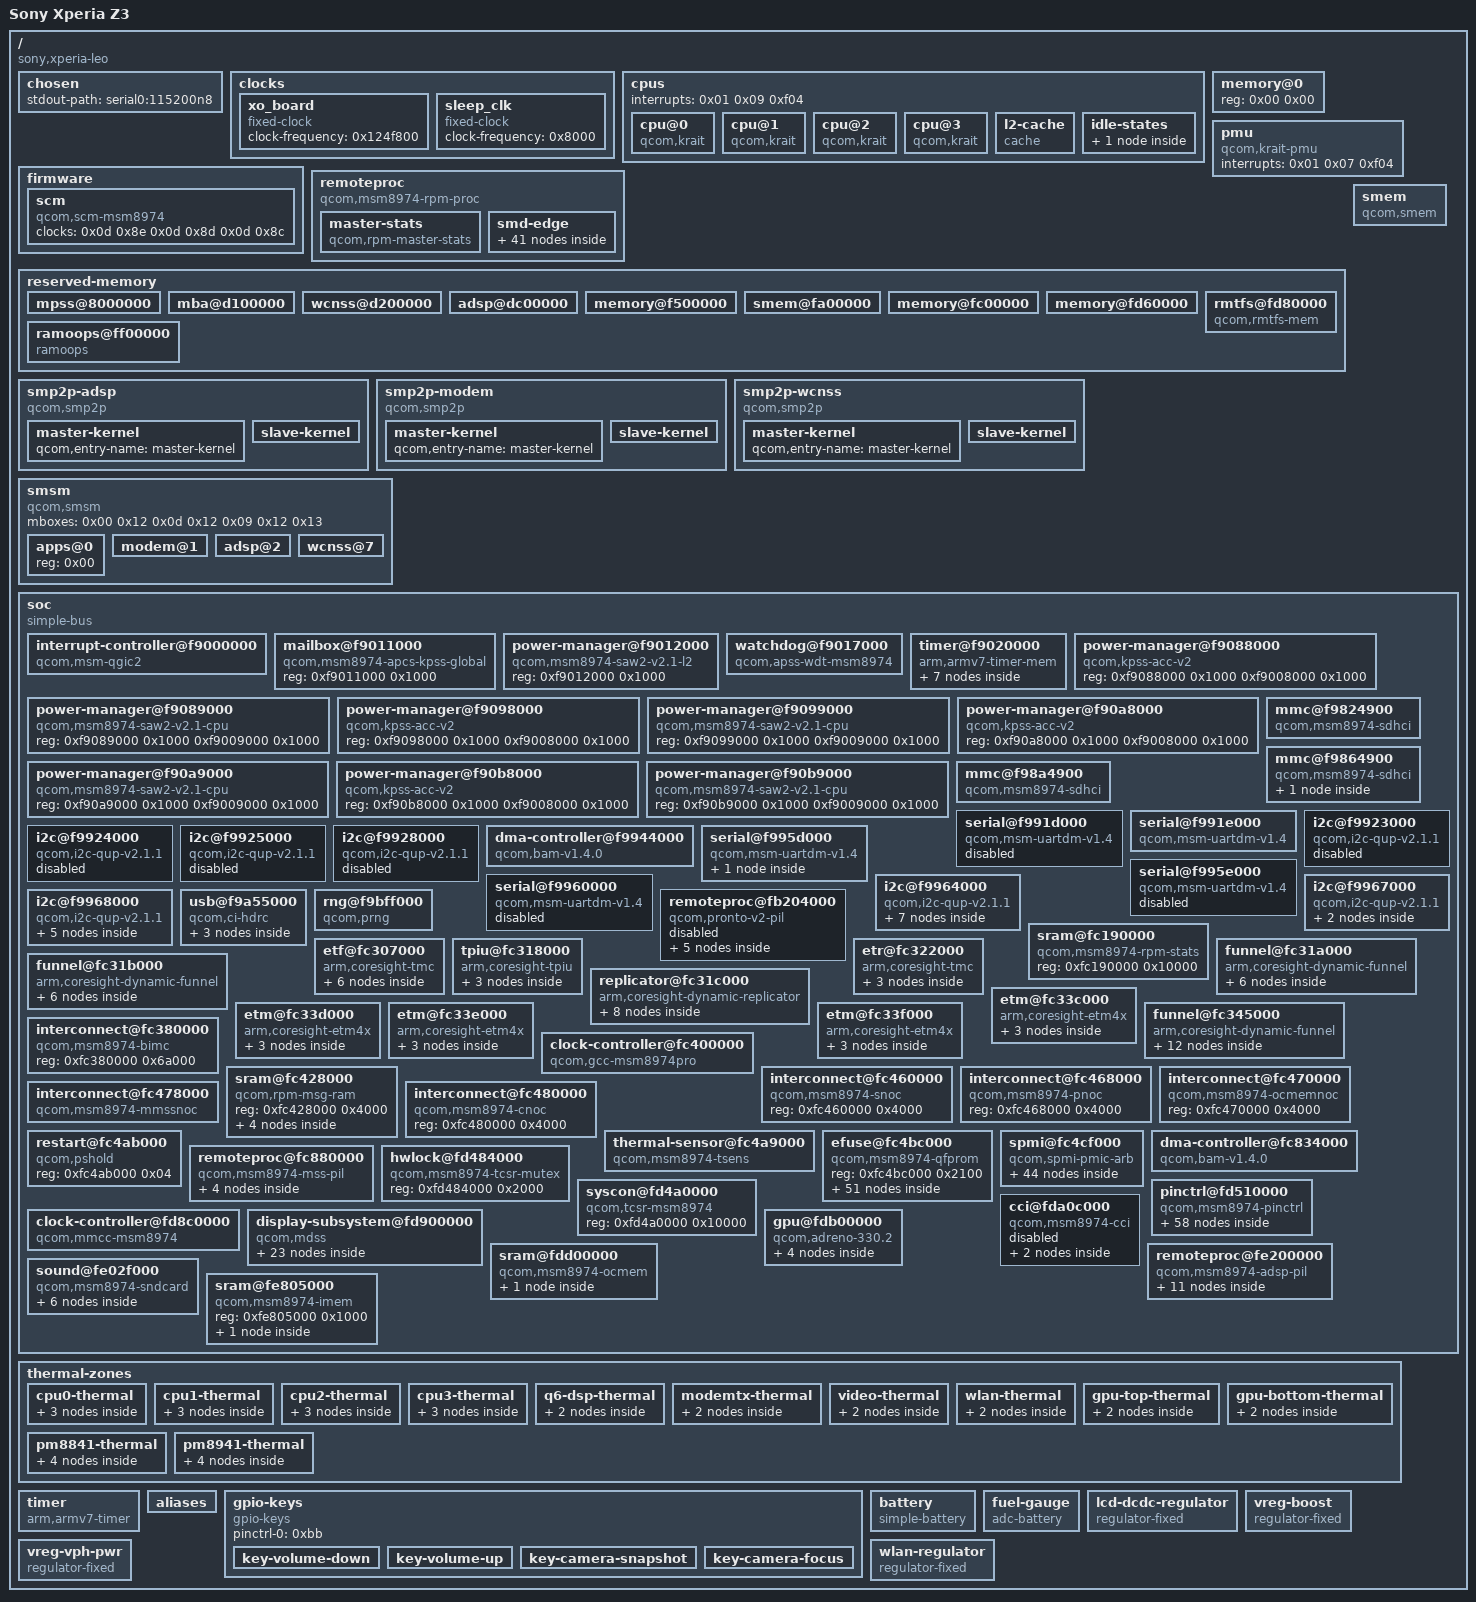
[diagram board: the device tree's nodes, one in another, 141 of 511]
/dts-v1/;

/ {
	#address-cells = <0x01>;
	#size-cells = <0x01>;
	interrupt-parent = <0x01>;
	model = "Sony Xperia Z3";
	compatible = "sony,xperia-leo", "qcom,msm8974pro", "qcom,msm8974";
	chassis-type = "handset";

	chosen {
		stdout-path = "serial0:115200n8";
	};

	clocks {

		xo_board {
			compatible = "fixed-clock";
			#clock-cells = <0x00>;
			clock-frequency = <0x124f800>;
			phandle = <0x13>;
		};

		sleep_clk {
			compatible = "fixed-clock";
			#clock-cells = <0x00>;
			clock-frequency = <0x8000>;
			phandle = <0x1c>;
		};
	};

	cpus {
		#address-cells = <0x01>;
		#size-cells = <0x00>;
		interrupts = <0x01 0x09 0xf04>;

		cpu@0 {
			compatible = "qcom,krait";
			enable-method = "qcom,kpss-acc-v2";
			device_type = "cpu";
			reg = <0x00>;
			next-level-cache = <0x02>;
			qcom,acc = <0x03>;
			qcom,saw = <0x04>;
			cpu-idle-states = <0x05>;
			phandle = <0x57>;
		};

		cpu@1 {
			compatible = "qcom,krait";
			enable-method = "qcom,kpss-acc-v2";
			device_type = "cpu";
			reg = <0x01>;
			next-level-cache = <0x02>;
			qcom,acc = <0x06>;
			qcom,saw = <0x07>;
			cpu-idle-states = <0x05>;
			phandle = <0x59>;
		};

		cpu@2 {
			compatible = "qcom,krait";
			enable-method = "qcom,kpss-acc-v2";
			device_type = "cpu";
			reg = <0x02>;
			next-level-cache = <0x02>;
			qcom,acc = <0x08>;
			qcom,saw = <0x09>;
			cpu-idle-states = <0x05>;
			phandle = <0x5b>;
		};

		cpu@3 {
			compatible = "qcom,krait";
			enable-method = "qcom,kpss-acc-v2";
			device_type = "cpu";
			reg = <0x03>;
			next-level-cache = <0x02>;
			qcom,acc = <0x0a>;
			qcom,saw = <0x0b>;
			cpu-idle-states = <0x05>;
			phandle = <0x5d>;
		};

		l2-cache {
			compatible = "cache";
			cache-level = <0x02>;
			cache-unified;
			qcom,saw = <0x0c>;
			phandle = <0x02>;
		};

		idle-states {

			cpu-spc {
				compatible = "qcom,idle-state-spc", "arm,idle-state";
				entry-latency-us = <0x96>;
				exit-latency-us = <0xc8>;
				min-residency-us = <0x7d0>;
				phandle = <0x05>;
			};
		};
	};

	firmware {

		scm {
			compatible = "qcom,scm-msm8974", "qcom,scm";
			clocks = <0x0d 0x8e 0x0d 0x8d 0x0d 0x8c>;
			clock-names = "core", "bus", "iface";
		};
	};

	memory@0 {
		device_type = "memory";
		reg = <0x00 0x00>;
	};

	pmu {
		compatible = "qcom,krait-pmu";
		interrupts = <0x01 0x07 0xf04>;
	};

	remoteproc {
		compatible = "qcom,msm8974-rpm-proc", "qcom,rpm-proc";

		master-stats {
			compatible = "qcom,rpm-master-stats";
			qcom,rpm-msg-ram = <0x0e 0x0f 0x10 0x11>;
			qcom,master-names = "APSS", "MPSS", "LPSS", "PRONTO";
		};

		smd-edge {
			interrupts = <0x00 0xa8 0x01>;
			mboxes = <0x12 0x00>;
			qcom,smd-edge = <0x0f>;

			rpm-requests {
				compatible = "qcom,rpm-msm8974", "qcom,smd-rpm";
				qcom,smd-channels = "rpm_requests";

				clock-controller {
					compatible = "qcom,rpmcc-msm8974", "qcom,rpmcc";
					#clock-cells = <0x01>;
					clocks = <0x13>;
					clock-names = "xo";
					phandle = <0x49>;
				};

				power-controller {
					compatible = "qcom,msm8974-rpmpd";
					#power-domain-cells = <0x01>;
					operating-points-v2 = <0x14>;
					phandle = <0x47>;

					opp-table {
						compatible = "operating-points-v2";
						phandle = <0x14>;

						opp1 {
							opp-level = <0x01>;
						};

						opp2 {
							opp-level = <0x02>;
						};

						opp3 {
							opp-level = <0x03>;
						};

						opp4 {
							opp-level = <0x04>;
						};

						opp5 {
							opp-level = <0x05>;
						};

						opp6 {
							opp-level = <0x06>;
						};
					};
				};

				regulators-0 {
					compatible = "qcom,rpm-pm8841-regulators";

					s1 {
						regulator-min-microvolt = <0xa4cb8>;
						regulator-max-microvolt = <0x100590>;
						phandle = <0xa1>;
					};

					s3 {
						regulator-min-microvolt = <0x7a120>;
						regulator-max-microvolt = <0x100590>;
						phandle = <0xa0>;
					};
				};

				regulators-1 {
					compatible = "qcom,rpm-pm8941-regulators";
					vdd_l1_l3-supply = <0x15>;
					vdd_l2_lvs1_2_3-supply = <0x16>;
					vdd_l4_l11-supply = <0x15>;
					vdd_l5_l7-supply = <0x17>;
					vdd_l6_l12_l14_l15-supply = <0x17>;
					vdd_l9_l10_l17_l22-supply = <0x18>;
					vdd_l13_l20_l23_l24-supply = <0x18>;
					vdd_l21-supply = <0x18>;

					s1 {
						regulator-min-microvolt = <0x13d620>;
						regulator-max-microvolt = <0x13d620>;
						regulator-always-on;
						regulator-boot-on;
						phandle = <0x15>;
					};

					s2 {
						regulator-min-microvolt = <0x20ce70>;
						regulator-max-microvolt = <0x20ce70>;
						regulator-boot-on;
						phandle = <0x17>;
					};

					s3 {
						regulator-min-microvolt = <0x1b7740>;
						regulator-max-microvolt = <0x1b7740>;
						regulator-system-load = <0x25990>;
						regulator-always-on;
						regulator-boot-on;
						phandle = <0x16>;
					};

					s4 {
						regulator-min-microvolt = <0x4c4b40>;
						regulator-max-microvolt = <0x4c4b40>;
					};

					l1 {
						regulator-min-microvolt = <0x12b128>;
						regulator-max-microvolt = <0x12b128>;
						regulator-always-on;
						regulator-boot-on;
					};

					l2 {
						regulator-min-microvolt = <0x124f80>;
						regulator-max-microvolt = <0x124f80>;
						phandle = <0xc2>;
					};

					l3 {
						regulator-min-microvolt = <0x124f80>;
						regulator-max-microvolt = <0x124f80>;
					};

					l4 {
						regulator-min-microvolt = <0x12b128>;
						regulator-max-microvolt = <0x12b128>;
					};

					l5 {
						regulator-min-microvolt = <0x1b7740>;
						regulator-max-microvolt = <0x1b7740>;
					};

					l6 {
						regulator-min-microvolt = <0x1b7740>;
						regulator-max-microvolt = <0x1b7740>;
						regulator-boot-on;
						phandle = <0x43>;
					};

					l7 {
						regulator-min-microvolt = <0x1b7740>;
						regulator-max-microvolt = <0x1b7740>;
						regulator-boot-on;
					};

					l8 {
						regulator-min-microvolt = <0x1b7740>;
						regulator-max-microvolt = <0x1b7740>;
					};

					l9 {
						regulator-min-microvolt = <0x1b7740>;
						regulator-max-microvolt = <0x2d0370>;
					};

					l12 {
						regulator-min-microvolt = <0x1b7740>;
						regulator-max-microvolt = <0x1b7740>;
						regulator-always-on;
						regulator-boot-on;
						phandle = <0xa2>;
					};

					l13 {
						regulator-min-microvolt = <0x1b7740>;
						regulator-max-microvolt = <0x2d0370>;
						regulator-boot-on;
						phandle = <0x24>;
					};

					l14 {
						regulator-min-microvolt = <0x1b7740>;
						regulator-max-microvolt = <0x1b7740>;
					};

					l15 {
						regulator-min-microvolt = <0x1f47d0>;
						regulator-max-microvolt = <0x1f47d0>;
					};

					l16 {
						regulator-min-microvolt = <0x2932e0>;
						regulator-max-microvolt = <0x2932e0>;
						regulator-always-on;
					};

					l17 {
						regulator-min-microvolt = <0x2932e0>;
						regulator-max-microvolt = <0x2932e0>;
						regulator-always-on;
						phandle = <0xd0>;
					};

					l18 {
						regulator-min-microvolt = <0x2b7cd0>;
						regulator-max-microvolt = <0x2b7cd0>;
						regulator-always-on;
					};

					l20 {
						regulator-min-microvolt = <0x2d0370>;
						regulator-max-microvolt = <0x2d0370>;
						regulator-system-load = <0x7a120>;
						regulator-allow-set-load;
						regulator-boot-on;
						phandle = <0x1d>;
					};

					l21 {
						regulator-min-microvolt = <0x2d0370>;
						regulator-max-microvolt = <0x2d0370>;
						regulator-system-load = <0x7a120>;
						regulator-allow-set-load;
						regulator-boot-on;
						phandle = <0x23>;
					};

					l22 {
						regulator-min-microvolt = <0x2dc6c0>;
						regulator-max-microvolt = <0x2dc6c0>;
						phandle = <0x36>;
					};

					l23 {
						regulator-min-microvolt = <0x2ab980>;
						regulator-max-microvolt = <0x2ab980>;
					};

					l24 {
						regulator-min-microvolt = <0x2eebb8>;
						regulator-max-microvolt = <0x2eebb8>;
						regulator-boot-on;
						phandle = <0x44>;
					};

					lvs1 {
						regulator-always-on;
						phandle = <0xd1>;
					};

					lvs3 {
						phandle = <0xc3>;
					};
				};
			};
		};
	};

	reserved-memory {
		#address-cells = <0x01>;
		#size-cells = <0x01>;
		ranges;

		mpss@8000000 {
			reg = <0x8000000 0x5100000>;
			no-map;
			phandle = <0xa4>;
		};

		mba@d100000 {
			reg = <0xd100000 0x100000>;
			no-map;
			phandle = <0xa3>;
		};

		wcnss@d200000 {
			reg = <0xd200000 0xa00000>;
			no-map;
			phandle = <0x45>;
		};

		adsp@dc00000 {
			reg = <0xdc00000 0x1900000>;
			no-map;
			phandle = <0xb6>;
		};

		memory@f500000 {
			reg = <0xf500000 0x500000>;
			no-map;
		};

		smem@fa00000 {
			reg = <0xfa00000 0x200000>;
			no-map;
			phandle = <0x19>;
		};

		memory@fc00000 {
			reg = <0xfc00000 0x160000>;
			no-map;
		};

		memory@fd60000 {
			reg = <0xfd60000 0x20000>;
			no-map;
		};

		rmtfs@fd80000 {
			compatible = "qcom,rmtfs-mem";
			reg = <0xfd80000 0x180000>;
			no-map;
			qcom,client-id = <0x01>;
		};
		ramoops@ff00000 {
			compatible = "ramoops";
			reg = <0x0ff00000 0x100000>;
			console-size = <0x80000>;
			record-size = <0x20000>;
		};
	};

	smem {
		compatible = "qcom,smem";
		memory-region = <0x19>;
		qcom,rpm-msg-ram = <0x1a>;
		hwlocks = <0x1b 0x03>;
	};

	smp2p-adsp {
		compatible = "qcom,smp2p";
		qcom,smem = <0x1bb 0x1ad>;
		interrupt-parent = <0x01>;
		interrupts = <0x00 0x9e 0x01>;
		mboxes = <0x12 0x0a>;
		qcom,local-pid = <0x00>;
		qcom,remote-pid = <0x02>;

		master-kernel {
			qcom,entry-name = "master-kernel";
			#qcom,smem-state-cells = <0x01>;
			phandle = <0xb7>;
		};

		slave-kernel {
			qcom,entry-name = "slave-kernel";
			interrupt-controller;
			#interrupt-cells = <0x02>;
			phandle = <0xb5>;
		};
	};

	smp2p-modem {
		compatible = "qcom,smp2p";
		qcom,smem = <0x1b3 0x1ac>;
		interrupt-parent = <0x01>;
		interrupts = <0x00 0x1b 0x01>;
		mboxes = <0x12 0x0e>;
		qcom,local-pid = <0x00>;
		qcom,remote-pid = <0x01>;

		master-kernel {
			qcom,entry-name = "master-kernel";
			#qcom,smem-state-cells = <0x01>;
			phandle = <0x9f>;
		};

		slave-kernel {
			qcom,entry-name = "slave-kernel";
			interrupt-controller;
			#interrupt-cells = <0x02>;
			phandle = <0x9e>;
		};
	};

	smp2p-wcnss {
		compatible = "qcom,smp2p";
		qcom,smem = <0x1c3 0x1af>;
		interrupt-parent = <0x01>;
		interrupts = <0x00 0x8f 0x01>;
		mboxes = <0x12 0x12>;
		qcom,local-pid = <0x00>;
		qcom,remote-pid = <0x04>;

		master-kernel {
			qcom,entry-name = "master-kernel";
			#qcom,smem-state-cells = <0x01>;
			phandle = <0x48>;
		};

		slave-kernel {
			qcom,entry-name = "slave-kernel";
			interrupt-controller;
			#interrupt-cells = <0x02>;
			phandle = <0x46>;
		};
	};

	smsm {
		compatible = "qcom,smsm";
		#address-cells = <0x01>;
		#size-cells = <0x00>;
		mboxes = <0x00 0x12 0x0d 0x12 0x09 0x12 0x13>;

		apps@0 {
			reg = <0x00>;
			#qcom,smem-state-cells = <0x01>;
			phandle = <0x4b>;
		};

		modem@1 {
			reg = <0x01>;
			interrupts = <0x00 0x1a 0x01>;
			interrupt-controller;
			#interrupt-cells = <0x02>;
			phandle = <0xa5>;
		};

		adsp@2 {
			reg = <0x02>;
			interrupts = <0x00 0x9d 0x01>;
			interrupt-controller;
			#interrupt-cells = <0x02>;
		};

		wcnss@7 {
			reg = <0x07>;
			interrupts = <0x00 0x90 0x01>;
			interrupt-controller;
			#interrupt-cells = <0x02>;
		};
	};

	soc {
		#address-cells = <0x01>;
		#size-cells = <0x01>;
		ranges;
		compatible = "simple-bus";

		interrupt-controller@f9000000 {
			compatible = "qcom,msm-qgic2";
			interrupt-controller;
			#interrupt-cells = <0x03>;
			reg = <0xf9000000 0x1000 0xf9002000 0x1000>;
			phandle = <0x01>;
		};

		mailbox@f9011000 {
			compatible = "qcom,msm8974-apcs-kpss-global", "qcom,msm8994-apcs-kpss-global", "syscon";
			reg = <0xf9011000 0x1000>;
			#mbox-cells = <0x01>;
			phandle = <0x12>;
		};

		power-manager@f9012000 {
			compatible = "qcom,msm8974-saw2-v2.1-l2", "qcom,saw2";
			reg = <0xf9012000 0x1000>;
			phandle = <0x0c>;
		};

		watchdog@f9017000 {
			compatible = "qcom,apss-wdt-msm8974", "qcom,kpss-wdt";
			reg = <0xf9017000 0x1000>;
			interrupts = <0x00 0x03 0x01 0x00 0x04 0x01>;
			clocks = <0x1c>;
		};

		timer@f9020000 {
			#address-cells = <0x01>;
			#size-cells = <0x01>;
			ranges;
			compatible = "arm,armv7-timer-mem";
			reg = <0xf9020000 0x1000>;
			clock-frequency = <0x124f800>;

			frame@f9021000 {
				frame-number = <0x00>;
				interrupts = <0x00 0x08 0x04 0x00 0x07 0x04>;
				reg = <0xf9021000 0x1000 0xf9022000 0x1000>;
			};

			frame@f9023000 {
				frame-number = <0x01>;
				interrupts = <0x00 0x09 0x04>;
				reg = <0xf9023000 0x1000>;
				status = "disabled";
			};

			frame@f9024000 {
				frame-number = <0x02>;
				interrupts = <0x00 0x0a 0x04>;
				reg = <0xf9024000 0x1000>;
				status = "disabled";
			};

			frame@f9025000 {
				frame-number = <0x03>;
				interrupts = <0x00 0x0b 0x04>;
				reg = <0xf9025000 0x1000>;
				status = "disabled";
			};

			frame@f9026000 {
				frame-number = <0x04>;
				interrupts = <0x00 0x0c 0x04>;
				reg = <0xf9026000 0x1000>;
				status = "disabled";
			};

			frame@f9027000 {
				frame-number = <0x05>;
				interrupts = <0x00 0x0d 0x04>;
				reg = <0xf9027000 0x1000>;
				status = "disabled";
			};

			frame@f9028000 {
				frame-number = <0x06>;
				interrupts = <0x00 0x0e 0x04>;
				reg = <0xf9028000 0x1000>;
				status = "disabled";
			};
		};

		power-manager@f9088000 {
			compatible = "qcom,kpss-acc-v2";
			reg = <0xf9088000 0x1000 0xf9008000 0x1000>;
			phandle = <0x03>;
		};

		power-manager@f9089000 {
			compatible = "qcom,msm8974-saw2-v2.1-cpu", "qcom,saw2";
			reg = <0xf9089000 0x1000 0xf9009000 0x1000>;
			phandle = <0x04>;
		};

		power-manager@f9098000 {
			compatible = "qcom,kpss-acc-v2";
			reg = <0xf9098000 0x1000 0xf9008000 0x1000>;
			phandle = <0x06>;
		};

		power-manager@f9099000 {
			compatible = "qcom,msm8974-saw2-v2.1-cpu", "qcom,saw2";
			reg = <0xf9099000 0x1000 0xf9009000 0x1000>;
			phandle = <0x07>;
		};

		power-manager@f90a8000 {
			compatible = "qcom,kpss-acc-v2";
			reg = <0xf90a8000 0x1000 0xf9008000 0x1000>;
			phandle = <0x08>;
		};

		power-manager@f90a9000 {
			compatible = "qcom,msm8974-saw2-v2.1-cpu", "qcom,saw2";
			reg = <0xf90a9000 0x1000 0xf9009000 0x1000>;
			phandle = <0x09>;
		};

		power-manager@f90b8000 {
			compatible = "qcom,kpss-acc-v2";
			reg = <0xf90b8000 0x1000 0xf9008000 0x1000>;
			phandle = <0x0a>;
		};

		power-manager@f90b9000 {
			compatible = "qcom,msm8974-saw2-v2.1-cpu", "qcom,saw2";
			reg = <0xf90b9000 0x1000 0xf9009000 0x1000>;
			phandle = <0x0b>;
		};

		mmc@f9824900 {
			compatible = "qcom,msm8974-sdhci", "qcom,sdhci-msm-v4";
			reg = <0xf9824900 0x11c 0xf9824000 0x800>;
			reg-names = "hc", "core";
			interrupts = <0x00 0x7b 0x04 0x00 0x8a 0x04>;
			interrupt-names = "hc_irq", "pwr_irq";
			clocks = <0x0d 0xd7 0x0d 0xd8 0x13 0x0d 0x131 0x0d 0x130>;
			clock-names = "iface", "core", "xo", "cal", "sleep";
			bus-width = <0x08>;
			non-removable;
			status = "okay";
			vmmc-supply = <0x1d>;
			vqmmc-supply = <0x16>;
			pinctrl-0 = <0x1e>;
			pinctrl-1 = <0x1f>;
			pinctrl-names = "default", "sleep";
		};

		mmc@f9864900 {
			compatible = "qcom,msm8974-sdhci", "qcom,sdhci-msm-v4";
			reg = <0xf9864900 0x11c 0xf9864000 0x800>;
			reg-names = "hc", "core";
			interrupts = <0x00 0x7f 0x04 0x00 0xe0 0x04>;
			interrupt-names = "hc_irq", "pwr_irq";
			clocks = <0x0d 0xdd 0x0d 0xde 0x13>;
			clock-names = "iface", "core", "xo";
			bus-width = <0x04>;
			#address-cells = <0x01>;
			#size-cells = <0x00>;
			status = "okay";
			max-frequency = <0x5f5e100>;
			vmmc-supply = <0x20>;
			non-removable;
			pinctrl-0 = <0x21>;
			pinctrl-names = "default";

			wifi@1 {
				compatible = "brcm,bcm4339-fmac", "brcm,bcm4329-fmac";
				reg = <0x01>;
				brcm,drive-strength = <0x0a>;
				pinctrl-0 = <0x22>;
				pinctrl-names = "default";
			};
		};

		mmc@f98a4900 {
			compatible = "qcom,msm8974-sdhci", "qcom,sdhci-msm-v4";
			reg = <0xf98a4900 0x11c 0xf98a4000 0x800>;
			reg-names = "hc", "core";
			interrupts = <0x00 0x7d 0x04 0x00 0xdd 0x04>;
			interrupt-names = "hc_irq", "pwr_irq";
			clocks = <0x0d 0xda 0x0d 0xdb 0x13>;
			clock-names = "iface", "core", "xo";
			bus-width = <0x04>;
			#address-cells = <0x01>;
			#size-cells = <0x00>;
			status = "okay";
			vmmc-supply = <0x23>;
			vqmmc-supply = <0x24>;
			cd-gpios = <0x25 0x3e 0x01>;
			pinctrl-0 = <0x26>;
			pinctrl-1 = <0x27>;
			pinctrl-names = "default", "sleep";
		};

		serial@f991d000 {
			compatible = "qcom,msm-uartdm-v1.4", "qcom,msm-uartdm";
			reg = <0xf991d000 0x1000>;
			interrupts = <0x00 0x6b 0x04>;
			clocks = <0x0d 0x65 0x0d 0x57>;
			clock-names = "core", "iface";
			status = "disabled";
		};

		serial@f991e000 {
			compatible = "qcom,msm-uartdm-v1.4", "qcom,msm-uartdm";
			reg = <0xf991e000 0x1000>;
			interrupts = <0x00 0x6c 0x04>;
			clocks = <0x0d 0x67 0x0d 0x57>;
			clock-names = "core", "iface";
			pinctrl-names = "default";
			pinctrl-0 = <0x28>;
			status = "okay";
		};

		i2c@f9923000 {
			status = "disabled";
			compatible = "qcom,i2c-qup-v2.1.1";
			reg = <0xf9923000 0x1000>;
			interrupts = <0x00 0x5f 0x04>;
			clocks = <0x0d 0x59 0x0d 0x57>;
			clock-names = "core", "iface";
			pinctrl-names = "default", "sleep";
			pinctrl-0 = <0x29>;
			pinctrl-1 = <0x2a>;
			#address-cells = <0x01>;
			#size-cells = <0x00>;
		};

		i2c@f9924000 {
			status = "disabled";
			compatible = "qcom,i2c-qup-v2.1.1";
			reg = <0xf9924000 0x1000>;
			interrupts = <0x00 0x60 0x04>;
			clocks = <0x0d 0x5b 0x0d 0x57>;
			clock-names = "core", "iface";
			pinctrl-names = "default", "sleep";
			pinctrl-0 = <0x2b>;
			pinctrl-1 = <0x2c>;
			#address-cells = <0x01>;
			#size-cells = <0x00>;
		};

		i2c@f9925000 {
			status = "disabled";
			compatible = "qcom,i2c-qup-v2.1.1";
			reg = <0xf9925000 0x1000>;
			interrupts = <0x00 0x61 0x04>;
			clocks = <0x0d 0x5d 0x0d 0x57>;
			clock-names = "core", "iface";
			pinctrl-names = "default", "sleep";
			pinctrl-0 = <0x2d>;
			pinctrl-1 = <0x2e>;
			#address-cells = <0x01>;
			#size-cells = <0x00>;
		};

		i2c@f9928000 {
			status = "disabled";
			compatible = "qcom,i2c-qup-v2.1.1";
			reg = <0xf9928000 0x1000>;
			interrupts = <0x00 0x64 0x04>;
			clocks = <0x0d 0x63 0x0d 0x57>;
			clock-names = "core", "iface";
			pinctrl-names = "default", "sleep";
			pinctrl-0 = <0x2f>;
			pinctrl-1 = <0x30>;
			#address-cells = <0x01>;
			#size-cells = <0x00>;
		};

		dma-controller@f9944000 {
			compatible = "qcom,bam-v1.4.0";
			reg = <0xf9944000 0x19000>;
			interrupts = <0x00 0xef 0x04>;
			clocks = <0x0d 0x71>;
			clock-names = "bam_clk";
			#dma-cells = <0x01>;
			qcom,ee = <0x00>;
			phandle = <0x38>;
		};

		serial@f995d000 {
			compatible = "qcom,msm-uartdm-v1.4", "qcom,msm-uartdm";
			reg = <0xf995d000 0x1000>;
			interrupts = <0x00 0x71 0x04>;
			clocks = <0x0d 0x7f 0x0d 0x71>;
			clock-names = "core", "iface";
			pinctrl-names = "default", "sleep";
			pinctrl-0 = <0x31>;
			pinctrl-1 = <0x32>;
			status = "okay";
			
			bluetooth {
				pinctrl-0 = <0xc0 0xc1 0xbf>;
				pinctrl-names = "default";
				compatible = "brcm,bcm43438-bt";
				max-speed = <0x2dc6c0>;
				host-wakeup-gpios = <0x25 0x5f 0x00>;
				device-wakeup-gpios = <0x25 0x60 0x00>;
				shutdown-gpios = <0x9a 0x10 0x00>;
			};
		};

		serial@f995e000 {
			compatible = "qcom,msm-uartdm-v1.4", "qcom,msm-uartdm";
			reg = <0xf995e000 0x1000>;
			interrupts = <0x00 0x72 0x04>;
			clocks = <0x0d 0x81 0x0d 0x71>;
			clock-names = "core", "iface";
			status = "disabled";
		};

		serial@f9960000 {
			compatible = "qcom,msm-uartdm-v1.4", "qcom,msm-uartdm";
			reg = <0xf9960000 0x1000>;
			interrupts = <0x00 0x74 0x04>;
			clocks = <0x0d 0x85 0x0d 0x71>;
			clock-names = "core", "iface";
			pinctrl-names = "default";
			pinctrl-0 = <0x33>;
			status = "disabled";
		};

		i2c@f9964000 {
			status = "okay";
			compatible = "qcom,i2c-qup-v2.1.1";
			reg = <0xf9964000 0x1000>;
			interrupts = <0x00 0x66 0x04>;
			clocks = <0x0d 0x75 0x0d 0x71>;
			clock-names = "core", "iface";
			pinctrl-names = "default", "sleep";
			pinctrl-0 = <0x34>;
			pinctrl-1 = <0x35>;
			#address-cells = <0x01>;
			#size-cells = <0x00>;
			clock-frequency = <0x56ab8>;

			maxim_max1187x_tsc@48 {
				compatible = "maxim,max1187x_tsc";
				reg = <0x48>;
				interrupt-parent = <0x25>;
				interrupts = <86 0x2>;
				vdd-supply = <0x36>;
				touch_vdd-supply_name = "vdd";
				tirq-gpio = <0x25 86 0x2>;
				reset-gpio = <0x25 85 0x2>;
				reset_l2h = <1>;
				enable_resume_por = <1>;
				defaults_allow = <0>;
				default_config_id = <0>;
				default_chip_id = <0>;
				fw_name = "touch_chip_id_0x%02x_config_id_0x%%04x.bin";
				i2c_words = <128>;
				coordinate_settings = <0x4>;
				panel_margin_xl = <0>;
				lcd_x = <1080>;
				panel_margin_xh = <0>;
				panel_margin_yl = <0>;
				lcd_y = <1920>;
				panel_margin_yh = <0>;
				num_sensor_x = <20>;
				num_sensor_y = <34>;
				button_code0 = <0>;
				button_code1 = <0>;
				button_code2 = <0>;
				button_code3 = <0>;
				touch_pressure_enabled = <1>;
				touch_size_enabled = <0>;
				touch_orientation_enabled = <0>;
				glove_enabled = <0>;
				report_pen_as_finger = <1>;
				wakeup_gesture_support = <1>;
				wakeup_gesture_timeout = <2000>;
				wakeup_gesture {
					double_tap {
						gesture_code = <0x0102>;
						event_00 {
							type = <2>; /* LOG */
							message = "=== DOUBLE TAP ===";
						};
						event_01 {
							type = <1>; /* KEY */
							code = <116>; /* KEY_POWER */
							down = <1>;
						};
						event_02 {
							type = <1>; /* KEY */
							code = <116>; /* KEY_POWER */
							down = <0>;
						};
						event_03 {
							type = <99>; /* END */
						};
					};
				};
			};
		};

		i2c@f9967000 {
			status = "okay";
			compatible = "qcom,i2c-qup-v2.1.1";
			reg = <0xf9967000 0x1000>;
			interrupts = <0x00 0x69 0x04>;
			clocks = <0x0d 0x7b 0x0d 0x71>;
			clock-names = "core", "iface";
			dmas = <0x38 0x14 0x38 0x15>;
			dma-names = "tx", "rx";
			pinctrl-names = "default", "sleep";
			pinctrl-0 = <0x39>;
			pinctrl-1 = <0x3a>;
			#address-cells = <0x01>;
			#size-cells = <0x00>;

			amplifier@34 {
				compatible = "nxp,tfa9890";
				reg = <0x34>;
				#sound-dai-cells = <0x00>;
				sound-name-prefix = "Speaker Top";
				phandle = <0xcd>;
			};

			amplifier@35 {
				compatible = "nxp,tfa9890";
				reg = <0x35>;
				#sound-dai-cells = <0x00>;
				sound-name-prefix = "Speaker Bottom";
				phandle = <0xce>;
			};
		};

		i2c@f9968000 {
			status = "okay";
			compatible = "qcom,i2c-qup-v2.1.1";
			reg = <0xf9968000 0x1000>;
			interrupts = <0x00 0x6a 0x04>;
			clocks = <0x0d 0x7d 0x0d 0x71>;
			clock-names = "core", "iface";
			pinctrl-names = "default", "sleep";
			pinctrl-0 = <0x3b>;
			pinctrl-1 = <0x3c>;
			#address-cells = <0x01>;
			#size-cells = <0x00>;

			accelerometer@18 {
				compatible = "bosch,bma255";
				reg = <0x18>;
				interrupt-parent = <0x25>;
				interrupts = <0x49 0x01>;
				vdd-supply = <0xd0>;
				vddio-supply = <0xd1>;
				mount-matrix = "0", "-1", "0",
					       "1", "0", "0",
					       "0", "0", "1";
			};

			gyroscope@68 {
				compatible = "bosch,bmg160";
				reg = <0x68>;
				interrupt-parent = <0x25>;
				interrupts = <0x42 0x01>;
				vdd-supply = <0xd0>;
				vddio-supply = <0xd1>;
				mount-matrix = "0", "-1", "0",
					       "1", "0", "0",
					       "0", "0", "1";
			};

			magnetometer@c {
				compatible = "asahi-kasei,ak09911";
				reg = <0x0c>;
				vdd-supply = <0xd0>;
				vid-supply = <0xd1>;
				mount-matrix = "0", "0", "1",
					       "0", "-1", "0",
					       "1", "0", "0";
			};

			pressure@76 {
				compatible = "bosch,bmp280";
				reg = <0x76>;
				vddd-supply = <0xd0>;
				vdda-supply = <0xd1>;
			};

			light-sensor@39 {
				compatible = "avago,apds9930";
				reg = <0x39>;
				interrupt-parent = <0x25>;
				interrupts = <0x4a 0x02>;
				vdd-supply = <0xd0>;
				vddio-supply = <0xd1>;
			};
		};

		usb@f9a55000 {
			compatible = "qcom,ci-hdrc";
			reg = <0xf9a55000 0x200 0xf9a55200 0x200>;
			interrupts = <0x00 0x86 0x04>;
			clocks = <0x0d 0x107 0x0d 0x109>;
			clock-names = "iface", "core";
			assigned-clocks = <0x0d 0x109>;
			assigned-clock-rates = <0x47868c0>;
			resets = <0x0d 0x09>;
			reset-names = "core";
			phy_type = "ulpi";
			dr_mode = "otg";
			ahb-burst-config = <0x00>;
			phy-names = "usb-phy";
			status = "okay";
			#reset-cells = <0x01>;
			phys = <0x3d>;
			phy-select = <0x3e 0xb000 0x00>;
			extcon = <0x3f 0x40>;
			vbus-supply = <0x41>;
			hnp-disable;
			srp-disable;
			adp-disable;
			phandle = <0x42>;

			ulpi {

				phy-0 {
					compatible = "qcom,usb-hs-phy-msm8974", "qcom,usb-hs-phy";
					#phy-cells = <0x00>;
					clocks = <0x13 0x0d 0x102>;
					clock-names = "ref", "sleep";
					resets = <0x0d 0x0a 0x42 0x00>;
					reset-names = "phy", "por";
					status = "okay";
					v1p8-supply = <0x43>;
					v3p3-supply = <0x44>;
					extcon = <0x3f>;
					qcom,init-seq = [01 64];
					phandle = <0x3d>;
				};

				phy-1 {
					compatible = "qcom,usb-hs-phy-msm8974", "qcom,usb-hs-phy";
					#phy-cells = <0x00>;
					clocks = <0x13 0x0d 0x103>;
					clock-names = "ref", "sleep";
					resets = <0x0d 0x0b 0x42 0x01>;
					reset-names = "phy", "por";
					status = "disabled";
				};
			};
		};

		rng@f9bff000 {
			compatible = "qcom,prng";
			reg = <0xf9bff000 0x200>;
			clocks = <0x0d 0xc3>;
			clock-names = "core";
		};

		remoteproc@fb204000 {
			compatible = "qcom,pronto-v2-pil", "qcom,pronto";
			reg = <0xfb204000 0x2000 0xfb202000 0x1000 0xfb21b000 0x3000>;
			reg-names = "ccu", "dxe", "pmu";
			memory-region = <0x45>;
			interrupts-extended = <0x01 0x00 0x95 0x01 0x46 0x00 0x01 0x46 0x01 0x01 0x46 0x02 0x01 0x46 0x03 0x01>;
			interrupt-names = "wdog", "fatal", "ready", "handover", "stop-ack";
			power-domains = <0x47 0x00>;
			power-domain-names = "cx";
			qcom,smem-states = <0x48 0x00>;
			qcom,smem-state-names = "stop";
			status = "disabled";
			phandle = <0x4a>;

			iris {
				compatible = "qcom,wcn3680";
				clocks = <0x49 0x2c>;
				clock-names = "xo";
			};

			smd-edge {
				interrupts = <0x00 0x8e 0x01>;
				mboxes = <0x12 0x11>;
				qcom,smd-edge = <0x06>;

				wcnss {
					compatible = "qcom,wcnss";
					qcom,smd-channels = "WCNSS_CTRL";
					status = "disabled";
					qcom,mmio = <0x4a>;

					bluetooth {
						compatible = "qcom,wcnss-bt";
					};

					wifi {
						compatible = "qcom,wcnss-wlan";
						interrupts = <0x00 0x91 0x01 0x00 0x92 0x01>;
						interrupt-names = "tx", "rx";
						qcom,smem-states = <0x4b 0x0a 0x4b 0x09>;
						qcom,smem-state-names = "tx-enable", "tx-rings-empty";
					};
				};
			};
		};

		sram@fc190000 {
			compatible = "qcom,msm8974-rpm-stats";
			reg = <0xfc190000 0x10000>;
		};

		etf@fc307000 {
			compatible = "arm,coresight-tmc", "arm,primecell";
			reg = <0xfc307000 0x1000>;
			clocks = <0x49 0x08 0x49 0x09>;
			clock-names = "apb_pclk", "atclk";

			out-ports {

				port {

					endpoint {
						remote-endpoint = <0x4c>;
						phandle = <0x55>;
					};
				};
			};

			in-ports {

				port {

					endpoint {
						remote-endpoint = <0x4d>;
						phandle = <0x52>;
					};
				};
			};
		};

		tpiu@fc318000 {
			compatible = "arm,coresight-tpiu", "arm,primecell";
			reg = <0xfc318000 0x1000>;
			clocks = <0x49 0x08 0x49 0x09>;
			clock-names = "apb_pclk", "atclk";

			in-ports {

				port {

					endpoint {
						remote-endpoint = <0x4e>;
						phandle = <0x54>;
					};
				};
			};
		};

		funnel@fc31a000 {
			compatible = "arm,coresight-dynamic-funnel", "arm,primecell";
			reg = <0xfc31a000 0x1000>;
			clocks = <0x49 0x08 0x49 0x09>;
			clock-names = "apb_pclk", "atclk";

			in-ports {
				#address-cells = <0x01>;
				#size-cells = <0x00>;

				port@5 {
					reg = <0x05>;

					endpoint {
						remote-endpoint = <0x4f>;
						phandle = <0x63>;
					};
				};
			};

			out-ports {

				port {

					endpoint {
						remote-endpoint = <0x50>;
						phandle = <0x51>;
					};
				};
			};
		};

		funnel@fc31b000 {
			compatible = "arm,coresight-dynamic-funnel", "arm,primecell";
			reg = <0xfc31b000 0x1000>;
			clocks = <0x49 0x08 0x49 0x09>;
			clock-names = "apb_pclk", "atclk";

			in-ports {
				#address-cells = <0x01>;
				#size-cells = <0x00>;

				port@1 {
					reg = <0x01>;

					endpoint {
						remote-endpoint = <0x51>;
						phandle = <0x50>;
					};
				};
			};

			out-ports {

				port {

					endpoint {
						remote-endpoint = <0x52>;
						phandle = <0x4d>;
					};
				};
			};
		};

		replicator@fc31c000 {
			compatible = "arm,coresight-dynamic-replicator", "arm,primecell";
			reg = <0xfc31c000 0x1000>;
			clocks = <0x49 0x08 0x49 0x09>;
			clock-names = "apb_pclk", "atclk";

			out-ports {
				#address-cells = <0x01>;
				#size-cells = <0x00>;

				port@0 {
					reg = <0x00>;

					endpoint {
						remote-endpoint = <0x53>;
						phandle = <0x56>;
					};
				};

				port@1 {
					reg = <0x01>;

					endpoint {
						remote-endpoint = <0x54>;
						phandle = <0x4e>;
					};
				};
			};

			in-ports {

				port {

					endpoint {
						remote-endpoint = <0x55>;
						phandle = <0x4c>;
					};
				};
			};
		};

		etr@fc322000 {
			compatible = "arm,coresight-tmc", "arm,primecell";
			reg = <0xfc322000 0x1000>;
			clocks = <0x49 0x08 0x49 0x09>;
			clock-names = "apb_pclk", "atclk";

			in-ports {

				port {

					endpoint {
						remote-endpoint = <0x56>;
						phandle = <0x53>;
					};
				};
			};
		};

		etm@fc33c000 {
			compatible = "arm,coresight-etm4x", "arm,primecell";
			reg = <0xfc33c000 0x1000>;
			clocks = <0x49 0x08 0x49 0x09>;
			clock-names = "apb_pclk", "atclk";
			cpu = <0x57>;

			out-ports {

				port {

					endpoint {
						remote-endpoint = <0x58>;
						phandle = <0x5f>;
					};
				};
			};
		};

		etm@fc33d000 {
			compatible = "arm,coresight-etm4x", "arm,primecell";
			reg = <0xfc33d000 0x1000>;
			clocks = <0x49 0x08 0x49 0x09>;
			clock-names = "apb_pclk", "atclk";
			cpu = <0x59>;

			out-ports {

				port {

					endpoint {
						remote-endpoint = <0x5a>;
						phandle = <0x60>;
					};
				};
			};
		};

		etm@fc33e000 {
			compatible = "arm,coresight-etm4x", "arm,primecell";
			reg = <0xfc33e000 0x1000>;
			clocks = <0x49 0x08 0x49 0x09>;
			clock-names = "apb_pclk", "atclk";
			cpu = <0x5b>;

			out-ports {

				port {

					endpoint {
						remote-endpoint = <0x5c>;
						phandle = <0x61>;
					};
				};
			};
		};

		etm@fc33f000 {
			compatible = "arm,coresight-etm4x", "arm,primecell";
			reg = <0xfc33f000 0x1000>;
			clocks = <0x49 0x08 0x49 0x09>;
			clock-names = "apb_pclk", "atclk";
			cpu = <0x5d>;

			out-ports {

				port {

					endpoint {
						remote-endpoint = <0x5e>;
						phandle = <0x62>;
					};
				};
			};
		};

		funnel@fc345000 {
			compatible = "arm,coresight-dynamic-funnel", "arm,primecell";
			reg = <0xfc345000 0x1000>;
			clocks = <0x49 0x08 0x49 0x09>;
			clock-names = "apb_pclk", "atclk";

			in-ports {
				#address-cells = <0x01>;
				#size-cells = <0x00>;

				port@0 {
					reg = <0x00>;

					endpoint {
						remote-endpoint = <0x5f>;
						phandle = <0x58>;
					};
				};

				port@1 {
					reg = <0x01>;

					endpoint {
						remote-endpoint = <0x60>;
						phandle = <0x5a>;
					};
				};

				port@2 {
					reg = <0x02>;

					endpoint {
						remote-endpoint = <0x61>;
						phandle = <0x5c>;
					};
				};

				port@3 {
					reg = <0x03>;

					endpoint {
						remote-endpoint = <0x62>;
						phandle = <0x5e>;
					};
				};
			};

			out-ports {

				port {

					endpoint {
						remote-endpoint = <0x63>;
						phandle = <0x4f>;
					};
				};
			};
		};

		interconnect@fc380000 {
			reg = <0xfc380000 0x6a000>;
			compatible = "qcom,msm8974-bimc";
			#interconnect-cells = <0x01>;
			phandle = <0xab>;
		};

		clock-controller@fc400000 {
			compatible = "qcom,gcc-msm8974pro";
			#clock-cells = <0x01>;
			#reset-cells = <0x01>;
			#power-domain-cells = <0x01>;
			reg = <0xfc400000 0x4000>;
			clocks = <0x49 0x00 0x1c>;
			clock-names = "xo", "sleep_clk";
			phandle = <0x0d>;
		};

		sram@fc428000 {
			compatible = "qcom,rpm-msg-ram";
			reg = <0xfc428000 0x4000>;
			#address-cells = <0x01>;
			#size-cells = <0x01>;
			ranges = <0x00 0xfc428000 0x4000>;
			phandle = <0x1a>;

			sram@150 {
				reg = <0x150 0x14>;
				phandle = <0x0e>;
			};

			sram@b50 {
				reg = <0xb50 0x14>;
				phandle = <0x0f>;
			};

			sram@1550 {
				reg = <0x1550 0x14>;
				phandle = <0x10>;
			};

			sram@1f50 {
				reg = <0x1f50 0x14>;
				phandle = <0x11>;
			};
		};

		interconnect@fc460000 {
			reg = <0xfc460000 0x4000>;
			compatible = "qcom,msm8974-snoc";
			#interconnect-cells = <0x01>;
		};

		interconnect@fc468000 {
			reg = <0xfc468000 0x4000>;
			compatible = "qcom,msm8974-pnoc";
			#interconnect-cells = <0x01>;
		};

		interconnect@fc470000 {
			reg = <0xfc470000 0x4000>;
			compatible = "qcom,msm8974-ocmemnoc";
			#interconnect-cells = <0x01>;
			phandle = <0xb4>;
		};

		interconnect@fc478000 {
			reg = <0xfc478000 0x4000>;
			compatible = "qcom,msm8974-mmssnoc";
			#interconnect-cells = <0x01>;
			clocks = <0x64 0x72>;
			clock-names = "bus";
			phandle = <0xaa>;
		};

		interconnect@fc480000 {
			reg = <0xfc480000 0x4000>;
			compatible = "qcom,msm8974-cnoc";
			#interconnect-cells = <0x01>;
		};

		thermal-sensor@fc4a9000 {
			compatible = "qcom,msm8974-tsens", "qcom,tsens-v0_1";
			reg = <0xfc4a9000 0x1000 0xfc4a8000 0x1000>;
			nvmem-cells = <0x65 0x66 0x67 0x68 0x69 0x6a 0x6b 0x6c 0x6d 0x6e 0x6f 0x70 0x71 0x72 0x73 0x74 0x75 0x76 0x77 0x78 0x79 0x7a 0x7b 0x7c 0x7d 0x7e 0x7f 0x80 0x81 0x82 0x83 0x84 0x85 0x86 0x87 0x88 0x89 0x8a 0x8b 0x8c 0x8d 0x8e 0x8f 0x90 0x91 0x92 0x93 0x94 0x95 0x96 0x97>;
			nvmem-cell-names = "mode", "base1", "base2", "use_backup", "mode_backup", "base1_backup", "base2_backup", "s0_p1", "s0_p2", "s1_p1", "s1_p2", "s2_p1", "s2_p2", "s3_p1", "s3_p2", "s4_p1", "s4_p2", "s5_p1", "s5_p2", "s6_p1", "s6_p2", "s7_p1", "s7_p2", "s8_p1", "s8_p2", "s9_p1", "s9_p2", "s10_p1", "s10_p2", "s0_p1_backup", "s0_p2_backup", "s1_p1_backup", "s1_p2_backup", "s2_p1_backup", "s2_p2_backup", "s3_p1_backup", "s3_p2_backup", "s4_p1_backup", "s4_p2_backup", "s5_p1_backup", "s5_p2_backup", "s6_p1_backup", "s6_p2_backup", "s7_p1_backup", "s7_p2_backup", "s8_p1_backup", "s8_p2_backup", "s9_p1_backup", "s9_p2_backup", "s10_p1_backup", "s10_p2_backup";
			#qcom,sensors = <0x0b>;
			interrupts = <0x00 0xb8 0x04>;
			interrupt-names = "uplow";
			#thermal-sensor-cells = <0x01>;
			phandle = <0xb8>;
		};

		restart@fc4ab000 {
			compatible = "qcom,pshold";
			reg = <0xfc4ab000 0x04>;
		};

		efuse@fc4bc000 {
			compatible = "qcom,msm8974-qfprom", "qcom,qfprom";
			reg = <0xfc4bc000 0x2100>;
			#address-cells = <0x01>;
			#size-cells = <0x01>;

			base1@d0 {
				reg = <0xd0 0x01>;
				bits = <0x00 0x08>;
				phandle = <0x66>;
			};

			s0-p1@d1 {
				reg = <0xd1 0x01>;
				bits = <0x00 0x06>;
				phandle = <0x6c>;
			};

			s1-p1@d2 {
				reg = <0xd1 0x02>;
				bits = <0x06 0x06>;
				phandle = <0x6e>;
			};

			s2-p1@d2 {
				reg = <0xd2 0x02>;
				bits = <0x04 0x06>;
				phandle = <0x70>;
			};

			s3-p1@d3 {
				reg = <0xd3 0x01>;
				bits = <0x02 0x06>;
				phandle = <0x72>;
			};

			s4-p1@d4 {
				reg = <0xd4 0x01>;
				bits = <0x00 0x06>;
				phandle = <0x74>;
			};

			s5-p1@d4 {
				reg = <0xd4 0x02>;
				bits = <0x06 0x06>;
				phandle = <0x76>;
			};

			s6-p1@d5 {
				reg = <0xd5 0x02>;
				bits = <0x04 0x06>;
				phandle = <0x78>;
			};

			s7-p1@d6 {
				reg = <0xd6 0x01>;
				bits = <0x02 0x06>;
				phandle = <0x7a>;
			};

			s8-p1@d7 {
				reg = <0xd7 0x01>;
				bits = <0x00 0x06>;
				phandle = <0x7c>;
			};

			mode@d7 {
				reg = <0xd7 0x01>;
				bits = <0x06 0x02>;
				phandle = <0x65>;
			};

			s9-p1@d8 {
				reg = <0xd8 0x01>;
				bits = <0x00 0x06>;
				phandle = <0x7e>;
			};

			s10-p1@d8 {
				reg = <0xd8 0x02>;
				bits = <0x06 0x06>;
				phandle = <0x80>;
			};

			base2@d9 {
				reg = <0xd9 0x02>;
				bits = <0x04 0x08>;
				phandle = <0x67>;
			};

			s0-p2@da {
				reg = <0xda 0x02>;
				bits = <0x04 0x06>;
				phandle = <0x6d>;
			};

			s1-p2@db {
				reg = <0xdb 0x01>;
				bits = <0x02 0x06>;
				phandle = <0x6f>;
			};

			s2-p2@dc {
				reg = <0xdc 0x01>;
				bits = <0x00 0x06>;
				phandle = <0x71>;
			};

			s3-p2@dc {
				reg = <0xdc 0x02>;
				bits = <0x06 0x06>;
				phandle = <0x73>;
			};

			s4-p2@dd {
				reg = <0xdd 0x02>;
				bits = <0x04 0x06>;
				phandle = <0x75>;
			};

			s5-p2@de {
				reg = <0xde 0x02>;
				bits = <0x02 0x06>;
				phandle = <0x77>;
			};

			s6-p2@df {
				reg = <0xdf 0x01>;
				bits = <0x00 0x06>;
				phandle = <0x79>;
			};

			s7-p2@e0 {
				reg = <0xe0 0x01>;
				bits = <0x00 0x06>;
				phandle = <0x7b>;
			};

			s8-p2@e0 {
				reg = <0xe0 0x02>;
				bits = <0x06 0x06>;
				phandle = <0x7d>;
			};

			s9-p2@e1 {
				reg = <0xe1 0x02>;
				bits = <0x04 0x06>;
				phandle = <0x7f>;
			};

			s10-p2@e2 {
				reg = <0xe2 0x02>;
				bits = <0x02 0x06>;
				phandle = <0x81>;
			};

			s5-p2-backup@e3 {
				reg = <0xe3 0x02>;
				bits = <0x00 0x06>;
				phandle = <0x8d>;
			};

			mode-backup@e3 {
				reg = <0xe3 0x01>;
				bits = <0x06 0x02>;
				phandle = <0x69>;
			};

			s6-p2-backup@e4 {
				reg = <0xe4 0x01>;
				bits = <0x00 0x06>;
				phandle = <0x8f>;
			};

			s7-p2-backup@e4 {
				reg = <0xe4 0x02>;
				bits = <0x06 0x06>;
				phandle = <0x91>;
			};

			s8-p2-backup@e5 {
				reg = <0xe5 0x02>;
				bits = <0x04 0x06>;
				phandle = <0x93>;
			};

			s9-p2-backup@e6 {
				reg = <0xe6 0x02>;
				bits = <0x02 0x06>;
				phandle = <0x95>;
			};

			s10-p2-backup@e7 {
				reg = <0xe7 0x01>;
				bits = <0x00 0x06>;
				phandle = <0x97>;
			};

			base1-backup@440 {
				reg = <0x440 0x01>;
				bits = <0x00 0x08>;
				phandle = <0x6a>;
			};

			s0-p1-backup@441 {
				reg = <0x441 0x01>;
				bits = <0x00 0x06>;
				phandle = <0x82>;
			};

			s1-p1-backup@442 {
				reg = <0x441 0x02>;
				bits = <0x06 0x06>;
				phandle = <0x84>;
			};

			s2-p1-backup@442 {
				reg = <0x442 0x02>;
				bits = <0x04 0x06>;
				phandle = <0x86>;
			};

			s3-p1-backup@443 {
				reg = <0x443 0x01>;
				bits = <0x02 0x06>;
				phandle = <0x88>;
			};

			s4-p1-backup@444 {
				reg = <0x444 0x01>;
				bits = <0x00 0x06>;
				phandle = <0x8a>;
			};

			s5-p1-backup@444 {
				reg = <0x444 0x02>;
				bits = <0x06 0x06>;
				phandle = <0x8c>;
			};

			s6-p1-backup@445 {
				reg = <0x445 0x02>;
				bits = <0x04 0x06>;
				phandle = <0x8e>;
			};

			s7-p1-backup@446 {
				reg = <0x446 0x01>;
				bits = <0x02 0x06>;
				phandle = <0x90>;
			};

			use-backup@447 {
				reg = <0x447 0x01>;
				bits = <0x05 0x03>;
				phandle = <0x68>;
			};

			s8-p1-backup@448 {
				reg = <0x448 0x01>;
				bits = <0x00 0x06>;
				phandle = <0x92>;
			};

			s9-p1-backup@448 {
				reg = <0x448 0x02>;
				bits = <0x06 0x06>;
				phandle = <0x94>;
			};

			s10-p1-backup@449 {
				reg = <0x449 0x02>;
				bits = <0x04 0x06>;
				phandle = <0x96>;
			};

			base2-backup@44a {
				reg = <0x44a 0x02>;
				bits = <0x02 0x08>;
				phandle = <0x6b>;
			};

			s0-p2-backup@44b {
				reg = <0x44b 0x03>;
				bits = <0x02 0x06>;
				phandle = <0x83>;
			};

			s1-p2-backup@44c {
				reg = <0x44c 0x01>;
				bits = <0x00 0x06>;
				phandle = <0x85>;
			};

			s2-p2-backup@44c {
				reg = <0x44c 0x02>;
				bits = <0x06 0x06>;
				phandle = <0x87>;
			};

			s3-p2-backup@44d {
				reg = <0x44d 0x02>;
				bits = <0x04 0x06>;
				phandle = <0x89>;
			};

			s4-p2-backup@44e {
				reg = <0x44e 0x01>;
				bits = <0x02 0x06>;
				phandle = <0x8b>;
			};
		};

		spmi@fc4cf000 {
			compatible = "qcom,spmi-pmic-arb";
			reg-names = "core", "intr", "cnfg";
			reg = <0xfc4cf000 0x1000 0xfc4cb000 0x1000 0xfc4ca000 0x1000>;
			interrupt-names = "periph_irq";
			interrupts = <0x00 0xbe 0x04>;
			qcom,ee = <0x00>;
			qcom,channel = <0x00>;
			#address-cells = <0x02>;
			#size-cells = <0x00>;
			interrupt-controller;
			#interrupt-cells = <0x04>;

			pm8841@4 {
				compatible = "qcom,pm8841", "qcom,spmi-pmic";
				reg = <0x04 0x00>;
				#address-cells = <0x01>;
				#size-cells = <0x00>;

				mpps@a000 {
					compatible = "qcom,pm8841-mpp", "qcom,spmi-mpp";
					reg = <0xa000>;
					gpio-controller;
					#gpio-cells = <0x02>;
					gpio-ranges = <0x98 0x00 0x00 0x04>;
					interrupt-controller;
					#interrupt-cells = <0x02>;
					phandle = <0x98>;
				};

				temp-alarm@2400 {
					compatible = "qcom,spmi-temp-alarm";
					reg = <0x2400>;
					interrupts = <0x04 0x24 0x00 0x01>;
					#thermal-sensor-cells = <0x00>;
					phandle = <0xb9>;
				};
			};

			pm8841@5 {
				compatible = "qcom,pm8841", "qcom,spmi-pmic";
				reg = <0x05 0x00>;
				#address-cells = <0x01>;
				#size-cells = <0x00>;
			};

			pm8941@0 {
				compatible = "qcom,pm8941", "qcom,spmi-pmic";
				reg = <0x00 0x00>;
				#address-cells = <0x01>;
				#size-cells = <0x00>;

				rtc@6000 {
					compatible = "qcom,pm8941-rtc";
					reg = <0x6000 0x6100>;
					reg-names = "rtc", "alarm";
					interrupts = <0x00 0x61 0x01 0x01>;
				};

				pon@800 {
					compatible = "qcom,pm8941-pon";
					reg = <0x800>;

					pwrkey {
						compatible = "qcom,pm8941-pwrkey";
						interrupts = <0x00 0x08 0x00 0x03>;
						debounce = <0x3d09>;
						bias-pull-up;
					};

					resin {
						compatible = "qcom,pm8941-resin";
						interrupts = <0x00 0x08 0x01 0x03>;
						debounce = <0x3d09>;
						bias-pull-up;
						status = "disabled";
					};
				};

				usb-detect@900 {
					compatible = "qcom,pm8941-misc";
					reg = <0x900>;
					interrupts = <0x00 0x09 0x00 0x03>;
					interrupt-names = "usb_id";
					phandle = <0x40>;
				};

				charger@1000 {
					compatible = "qcom,pm8941-charger";
					reg = <0x1000>;
					interrupts = <0x00 0x10 0x07 0x03 0x00 0x10 0x05 0x03 0x00 0x10 0x04 0x03 0x00 0x12 0x01 0x03 0x00 0x12 0x00 0x03 0x00 0x13 0x02 0x03 0x00 0x13 0x01 0x03 0x00 0x14 0x01 0x03>;
					interrupt-names = "chg-done", "chg-fast", "chg-trkl", "bat-temp-ok", "bat-present", "chg-gone", "usb-valid", "dc-valid";
					usb-otg-in-supply = <0x99>;
					status = "okay";
					usb-charge-current-limit = <0x16e360>;
					qcom,fast-charge-safe-current = <0x2dc6c0>;
					qcom,fast-charge-current-limit = <0x20ce70>;
					qcom,fast-charge-safe-voltage = <0x432380>;
					qcom,fast-charge-high-threshold-voltage = <0x426030>;
					qcom,auto-recharge-threshold-voltage = <0x414ec0>;
					qcom,minimum-input-voltage = <0x401640>;
					phandle = <0x3f>;

					otg-vbus {
						phandle = <0x41>;
					};
				};

				gpio@c000 {
					compatible = "qcom,pm8941-gpio", "qcom,spmi-gpio";
					reg = <0xc000>;
					gpio-controller;
					gpio-ranges = <0x9a 0x00 0x00 0x24>;
					#gpio-cells = <0x02>;
					interrupt-controller;
					#interrupt-cells = <0x02>;
					phandle = <0x9a>;

					boost-bypass-state {
						pins = "gpio21";
						function = "normal";
						phandle = <0xbd>;
					};

					gpio-keys-active-state {
						pins = "gpio2", "gpio3", "gpio4", "gpio5";
						function = "normal";
						bias-pull-up;
						power-source = <0x02>;
						phandle = <0xbb>;
					};

					wl-sleep-clk-state {
						pins = "gpio17";
						function = "func2";
						output-high;
						power-source = <0x02>;
						phandle = <0x22>;
					};

					wl-reg-active-state {
						pins = "gpio18";
						function = "normal";
						bias-disable;
						power-source = <0x02>;
						phandle = <0xbe>;
					};

					lcd-dcdc-en-active-state {
						pins = "gpio20";
						function = "normal";
						bias-disable;
						power-source = <0x02>;
						input-disable;
						output-low;
						phandle = <0xbc>;
					};

					bt-reg-on-state {
						pins = "gpio16";
						function = "normal";
						output-low;
						power-source = <0x02>;
						phandle = <0xbf>;
					};

					lcd-reset-state {
						pins = "gpio19";
						function = "normal";
						bias-disable;
						power-source = <0x02>;
						input-disable;
						output-high;
						phandle = <0xc6>;
					};
				};

				mpps@a000 {
					compatible = "qcom,pm8941-mpp", "qcom,spmi-mpp";
					reg = <0xa000>;
					gpio-controller;
					#gpio-cells = <0x02>;
					gpio-ranges = <0x9b 0x00 0x00 0x08>;
					interrupt-controller;
					#interrupt-cells = <0x02>;
					phandle = <0x9b>;
				};

				temp-alarm@2400 {
					compatible = "qcom,spmi-temp-alarm";
					reg = <0x2400>;
					interrupts = <0x00 0x24 0x00 0x01>;
					io-channels = <0x9c 0x08>;
					io-channel-names = "thermal";
					#thermal-sensor-cells = <0x00>;
					phandle = <0xba>;
				};

				adc@3100 {
					compatible = "qcom,spmi-vadc";
					reg = <0x3100>;
					interrupts = <0x00 0x31 0x00 0x01>;
					#address-cells = <0x01>;
					#size-cells = <0x00>;
					#io-channel-cells = <0x01>;
					phandle = <0x9c>;

					channel@6 {
						reg = <0x06>;
					};

					channel@8 {
						reg = <0x08>;
					};

					channel@9 {
						reg = <0x09>;
					};

					channel@a {
						reg = <0x0a>;
					};

					channel@e {
						reg = <0x0e>;
					};

					channel@f {
						reg = <0x0f>;
					};

					channel@30 {
						reg = <0x30>;
					};
				};

				adc@3600 {
					compatible = "qcom,pm8941-iadc", "qcom,spmi-iadc";
					reg = <0x3600>;
					interrupts = <0x00 0x36 0x00 0x01>;
					qcom,external-resistor-micro-ohms = <0x2710>;
				};

				charger@2800 {
					compatible = "qcom,pm8941-coincell";
					reg = <0x2800>;
					status = "okay";
					qcom,rset-ohms = <0x834>;
					qcom,vset-millivolts = <0xbb8>;
				};
			};

			pm8941@1 {
				compatible = "qcom,pm8941", "qcom,spmi-pmic";
				reg = <0x01 0x00>;
				#address-cells = <0x01>;
				#size-cells = <0x00>;

				pwm {
					compatible = "qcom,pm8941-lpg";
					#address-cells = <0x01>;
					#size-cells = <0x00>;
					#pwm-cells = <0x02>;
					status = "okay";
					qcom,power-source = <0x01>;

					multi-led {
						color = <0x09>;
						function = "status";
						#address-cells = <0x01>;
						#size-cells = <0x00>;

						led@5 {
							reg = <0x05>;
							color = <0x03>;
						};

						led@6 {
							reg = <0x06>;
							color = <0x02>;
						};

						led@7 {
							reg = <0x07>;
							color = <0x01>;
						};
					};
				};

				vibrator@c000 {
					compatible = "qcom,pm8916-vib";
					reg = <0xc000>;
					status = "okay";
				};

				wled@d800 {
					compatible = "qcom,pm8941-wled";
					reg = <0xd800>;
					label = "backlight";
					status = "okay";
					qcom,cs-out;
					qcom,current-limit = <0x14>;
					qcom,current-boost-limit = <0x325>;
					qcom,switching-freq = <0x640>;
					qcom,ovp = <0x1d>;
					qcom,num-strings = <0x02>;
					phandle = <0xc5>;
				};

				regulators {
					compatible = "qcom,pm8941-regulators";
					interrupts = <0x01 0x83 0x02 0x00 0x01 0x84 0x02 0x00>;
					interrupt-names = "ocp-5vs1", "ocp-5vs2";
					vin_5vs-supply = <0x9d>;

					s4 {
						regulator-min-microvolt = <0x4c4b40>;
						regulator-max-microvolt = <0x4c4b40>;
						regulator-enable-ramp-delay = <0x1f4>;
						phandle = <0x9d>;
					};

					5vs1 {
						regulator-enable-ramp-delay = <0x3e8>;
						regulator-pull-down;
						regulator-over-current-protection;
						qcom,ocp-max-retries = <0x0a>;
						qcom,ocp-retry-delay = <0x1e>;
						qcom,vs-soft-start-strength = <0x00>;
						regulator-initial-mode = <0x01>;
						phandle = <0x99>;
					};

					5vs2 {
						regulator-enable-ramp-delay = <0x3e8>;
						regulator-pull-down;
						regulator-over-current-protection;
						qcom,ocp-max-retries = <0x0a>;
						qcom,ocp-retry-delay = <0x1e>;
						qcom,vs-soft-start-strength = <0x00>;
						regulator-initial-mode = <0x01>;
					};
				};
			};
		};

		dma-controller@fc834000 {
			compatible = "qcom,bam-v1.4.0";
			reg = <0xfc834000 0x7000>;
			interrupts = <0x00 0x1d 0x04>;
			#dma-cells = <0x01>;
			qcom,ee = <0x00>;
			num-channels = <0x06>;
			qcom,num-ees = <0x01>;
			qcom,powered-remotely;
			phandle = <0xa6>;
		};

		remoteproc@fc880000 {
			compatible = "qcom,msm8974-mss-pil";
			reg = <0xfc880000 0x100 0xfc820000 0x20>;
			reg-names = "qdsp6", "rmb";
			interrupts-extended = <0x01 0x00 0x18 0x01 0x9e 0x00 0x01 0x9e 0x01 0x01 0x9e 0x02 0x01 0x9e 0x03 0x01>;
			interrupt-names = "wdog", "fatal", "ready", "handover", "stop-ack";
			clocks = <0x0d 0xb4 0x0d 0xb3 0x0d 0x8b 0x13>;
			clock-names = "iface", "bus", "mem", "xo";
			resets = <0x0d 0x4a>;
			reset-names = "mss_restart";
			power-domains = <0x47 0x00>;
			power-domain-names = "cx";
			qcom,halt-regs = <0x1b 0x1180 0x1200 0x1280>;
			qcom,smem-states = <0x9f 0x00>;
			qcom,smem-state-names = "stop";
			status = "okay";
			mss-supply = <0xa0>;
			mx-supply = <0xa1>;
			pll-supply = <0xa2>;

			mba {
				memory-region = <0xa3>;
			};

			mpss {
				memory-region = <0xa4>;
			};

			bam-dmux {
				compatible = "qcom,bam-dmux";
				interrupt-parent = <0xa5>;
				interrupts = <0x01 0x03 0x0b 0x03>;
				interrupt-names = "pc", "pc-ack";
				qcom,smem-states = <0x4b 0x01 0x4b 0x0b>;
				qcom,smem-state-names = "pc", "pc-ack";
				dmas = <0xa6 0x04 0xa6 0x05>;
				dma-names = "tx", "rx";
			};

			smd-edge {
				interrupts = <0x00 0x19 0x01>;
				mboxes = <0x12 0x0c>;
				qcom,smd-edge = <0x00>;
				label = "modem";
			};
		};

		hwlock@fd484000 {
			compatible = "qcom,msm8974-tcsr-mutex", "qcom,tcsr-mutex", "syscon";
			reg = <0xfd484000 0x2000>;
			#hwlock-cells = <0x01>;
			phandle = <0x1b>;
		};

		syscon@fd4a0000 {
			compatible = "qcom,tcsr-msm8974", "syscon";
			reg = <0xfd4a0000 0x10000>;
			phandle = <0x3e>;
		};

		pinctrl@fd510000 {
			compatible = "qcom,msm8974-pinctrl";
			reg = <0xfd510000 0x4000>;
			gpio-controller;
			gpio-ranges = <0x25 0x00 0x00 0x92>;
			#gpio-cells = <0x02>;
			interrupt-controller;
			#interrupt-cells = <0x02>;
			interrupts = <0x00 0xd0 0x04>;
			phandle = <0x25>;

			sdc1-off-state {
				phandle = <0x1f>;

				clk-pins {
					pins = "sdc1_clk";
					bias-disable;
					drive-strength = <0x02>;
				};

				cmd-pins {
					pins = "sdc1_cmd";
					bias-pull-up;
					drive-strength = <0x02>;
				};

				data-pins {
					pins = "sdc1_data";
					bias-pull-up;
					drive-strength = <0x02>;
				};
			};

			sdc2-off-state {
				phandle = <0x27>;

				clk-pins {
					pins = "sdc2_clk";
					bias-disable;
					drive-strength = <0x02>;
				};

				cmd-pins {
					pins = "sdc2_cmd";
					bias-pull-up;
					drive-strength = <0x02>;
				};

				data-pins {
					pins = "sdc2_data";
					bias-pull-up;
					drive-strength = <0x02>;
				};
			};

			blsp1-uart2-default-state {
				phandle = <0x28>;

				rx-pins {
					pins = "gpio5";
					function = "blsp_uart2";
					drive-strength = <0x02>;
					bias-pull-up;
				};

				tx-pins {
					pins = "gpio4";
					function = "blsp_uart2";
					drive-strength = <0x04>;
					bias-disable;
				};
			};

			blsp2-uart1-default-state {
				phandle = <0x31>;

				tx-rts-pins {
					pins = "gpio41", "gpio44";
					function = "blsp_uart7";
					drive-strength = <0x02>;
					bias-disable;
				};

				rx-cts-pins {
					pins = "gpio42", "gpio43";
					function = "blsp_uart7";
					drive-strength = <0x02>;
					bias-pull-up;
				};
			};

			blsp2-uart1-sleep-state {
				pins = "gpio41", "gpio42", "gpio43", "gpio44";
				function = "gpio";
				drive-strength = <0x02>;
				bias-pull-down;
				phandle = <0x32>;
			};

			blsp2-uart4-default-state {
				phandle = <0x33>;

				tx-rts-pins {
					pins = "gpio53", "gpio56";
					function = "blsp_uart10";
					drive-strength = <0x02>;
					bias-disable;
				};

				rx-cts-pins {
					pins = "gpio54", "gpio55";
					function = "blsp_uart10";
					drive-strength = <0x02>;
					bias-pull-up;
				};
			};

			blsp1-i2c1-default-state {
				pins = "gpio2", "gpio3";
				function = "blsp_i2c1";
				drive-strength = <0x02>;
				bias-disable;
				phandle = <0x29>;
			};

			blsp1-i2c1-sleep-state {
				pins = "gpio2", "gpio3";
				function = "blsp_i2c1";
				drive-strength = <0x02>;
				bias-pull-up;
				phandle = <0x2a>;
			};

			blsp1-i2c2-default-state {
				pins = "gpio6", "gpio7";
				function = "blsp_i2c2";
				drive-strength = <0x02>;
				bias-disable;
				phandle = <0x2b>;
			};

			blsp1-i2c2-sleep-state {
				pins = "gpio6", "gpio7";
				function = "blsp_i2c2";
				drive-strength = <0x02>;
				bias-pull-up;
				phandle = <0x2c>;
			};

			blsp1-i2c3-default-state {
				pins = "gpio10", "gpio11";
				function = "blsp_i2c3";
				drive-strength = <0x02>;
				bias-disable;
				phandle = <0x2d>;
			};

			blsp1-i2c3-sleep-state {
				pins = "gpio10", "gpio11";
				function = "blsp_i2c3";
				drive-strength = <0x02>;
				bias-pull-up;
				phandle = <0x2e>;
			};

			blsp1-i2c6-default-state {
				pins = "gpio29", "gpio30";
				function = "blsp_i2c6";
				drive-strength = <0x02>;
				bias-disable;
				phandle = <0x2f>;
			};

			blsp1-i2c6-sleep-state {
				pins = "gpio29", "gpio30";
				function = "blsp_i2c6";
				drive-strength = <0x02>;
				bias-pull-up;
				phandle = <0x30>;
			};

			blsp2-i2c2-default-state {
				pins = "gpio47", "gpio48";
				function = "blsp_i2c8";
				drive-strength = <0x02>;
				bias-disable;
				phandle = <0x34>;
			};

			blsp2-i2c2-sleep-state {
				pins = "gpio47", "gpio48";
				function = "blsp_i2c8";
				drive-strength = <0x02>;
				bias-pull-up;
				phandle = <0x35>;
			};

			blsp2-i2c5-default-state {
				pins = "gpio83", "gpio84";
				function = "blsp_i2c11";
				drive-strength = <0x02>;
				bias-disable;
				phandle = <0x39>;
			};

			blsp2-i2c5-sleep-state {
				pins = "gpio83", "gpio84";
				function = "blsp_i2c11";
				drive-strength = <0x02>;
				bias-pull-up;
				phandle = <0x3a>;
			};
			quat-mi2s-default-state {
				pins = "gpio58", "gpio59", "gpio60", "gpio61";
				function = "qua_mi2s";
				drive-strength = <0x08>;
				bias-disable;
				phandle = <0xcf>;
			};

			blsp2-i2c6-default-state {
				pins = "gpio87", "gpio88";
				function = "blsp_i2c12";
				drive-strength = <0x02>;
				bias-disable;
				phandle = <0x3b>;
			};

			blsp2-i2c6-sleep-state {
				pins = "gpio87", "gpio88";
				function = "blsp_i2c12";
				drive-strength = <0x02>;
				bias-pull-up;
				phandle = <0x3c>;
			};

			cci-default-state {
				phandle = <0xb0>;

				cci-i2c0-default-pins {
					pins = "gpio19", "gpio20";
					function = "cci_i2c0";
					drive-strength = <0x02>;
					bias-disable;
				};

				cci-i2c1-default-pins {
					pins = "gpio21", "gpio22";
					function = "cci_i2c1";
					drive-strength = <0x02>;
					bias-disable;
				};
			};

			cci-sleep-state {
				phandle = <0xb1>;

				cci-i2c0-sleep-pins {
					pins = "gpio19", "gpio20";
					function = "gpio";
					drive-strength = <0x02>;
					bias-disable;
				};

				cci-i2c1-sleep-pins {
					pins = "gpio21", "gpio22";
					function = "gpio";
					drive-strength = <0x02>;
					bias-disable;
				};
			};

			spi8_default-state {

				mosi-pins {
					pins = "gpio45";
					function = "blsp_spi8";
				};

				miso-pins {
					pins = "gpio46";
					function = "blsp_spi8";
				};

				cs-pins {
					pins = "gpio47";
					function = "blsp_spi8";
				};

				clk-pins {
					pins = "gpio48";
					function = "blsp_spi8";
				};
			};

			sdc1-on-state {
				phandle = <0x1e>;

				clk-pins {
					pins = "sdc1_clk";
					drive-strength = <0x10>;
					bias-disable;
				};

				cmd-data-pins {
					pins = "sdc1_cmd", "sdc1_data";
					drive-strength = <0x0a>;
					bias-pull-up;
				};
			};

			sdc2-on-state {
				phandle = <0x26>;

				clk-pins {
					pins = "sdc2_clk";
					drive-strength = <0x06>;
					bias-disable;
				};

				cmd-data-pins {
					pins = "sdc2_cmd", "sdc2_data";
					drive-strength = <0x06>;
					bias-pull-up;
				};

				cd-pins {
					pins = "gpio62";
					function = "gpio";
					drive-strength = <0x02>;
					bias-disable;
				};
			};

			sdc3-on-state {
				phandle = <0x21>;

				clk-pins {
					pins = "gpio40";
					function = "sdc3";
					drive-strength = <0x0a>;
					bias-disable;
				};

				cmd-pins {
					pins = "gpio39";
					function = "sdc3";
					drive-strength = <0x0a>;
					bias-pull-up;
				};

				data-pins {
					pins = "gpio35", "gpio36", "gpio37", "gpio38";
					function = "sdc3";
					drive-strength = <0x0a>;
					bias-pull-up;
				};
			};

			ts-int-pin-state {
				pins = "gpio86";
				function = "gpio";
				drive-strength = <0x02>;
				bias-disable;
				phandle = <0x37>;
			};

			bt-host-wake-state {
				pins = "gpio95";
				function = "gpio";
				drive-strength = <0x02>;
				bias-disable;
				output-low;
				phandle = <0xc0>;
			};

			bt-dev-wake-state {
				pins = "gpio96";
				function = "gpio";
				drive-strength = <0x02>;
				bias-disable;
				phandle = <0xc1>;
			};
		};

		clock-controller@fd8c0000 {
			compatible = "qcom,mmcc-msm8974";
			#clock-cells = <0x01>;
			#reset-cells = <0x01>;
			#power-domain-cells = <0x01>;
			reg = <0xfd8c0000 0x6000>;
			clocks = <0x13 0x0d 0x110 0x0d 0x01 0x0d 0x0d 0x49 0x20 0xa7 0x01 0xa7 0x00 0xa8 0x01 0xa8 0x00 0x00 0x00 0x00>;
			clock-names = "xo", "mmss_gpll0_vote", "gpll0_vote", "gpll1_vote", "gfx3d_clk_src", "dsi0pll", "dsi0pllbyte", "dsi1pll", "dsi1pllbyte", "hdmipll", "edp_link_clk", "edp_vco_div";
			phandle = <0x64>;
		};

		display-subsystem@fd900000 {
			compatible = "qcom,mdss";
			reg = <0xfd900000 0x100 0xfd924000 0x1000>;
			reg-names = "mdss_phys", "vbif_phys";
			power-domains = <0x64 0x01>;
			clocks = <0x64 0x5d 0x64 0x5e 0x64 0x6d>;
			clock-names = "iface", "bus", "vsync";
			interrupts = <0x00 0x48 0x04>;
			interrupt-controller;
			#interrupt-cells = <0x01>;
			status = "okay";
			#address-cells = <0x01>;
			#size-cells = <0x01>;
			ranges;
			phandle = <0xa9>;

			display-controller@fd900000 {
				compatible = "qcom,msm8974-mdp5", "qcom,mdp5";
				reg = <0xfd900100 0x22000>;
				reg-names = "mdp_phys";
				interrupt-parent = <0xa9>;
				interrupts = <0x00>;
				clocks = <0x64 0x5d 0x64 0x5e 0x64 0x69 0x64 0x6d>;
				clock-names = "iface", "bus", "core", "vsync";
				interconnects = <0xaa 0x02 0xab 0x05>;
				interconnect-names = "mdp0-mem";

				ports {
					#address-cells = <0x01>;
					#size-cells = <0x00>;

					port@0 {
						reg = <0x00>;

						endpoint {
							remote-endpoint = <0xac>;
							phandle = <0xae>;
						};
					};

					port@1 {
						reg = <0x01>;

						endpoint {
							remote-endpoint = <0xad>;
							phandle = <0xaf>;
						};
					};
				};
			};

			dsi@fd922800 {
				compatible = "qcom,msm8974-dsi-ctrl", "qcom,mdss-dsi-ctrl";
				reg = <0xfd922800 0x1f8>;
				reg-names = "dsi_ctrl";
				interrupt-parent = <0xa9>;
				interrupts = <0x04>;
				assigned-clocks = <0x64 0x21 0x64 0x13>;
				assigned-clock-parents = <0xa7 0x00 0xa7 0x01>;
				clocks = <0x64 0x69 0x64 0x5d 0x64 0x5e 0x64 0x5f 0x64 0x6b 0x64 0x64 0x64 0x6e>;
				clock-names = "mdp_core", "iface", "bus", "byte", "pixel", "core", "core_mmss";
				phys = <0xa7>;
				status = "okay";
				vdda-supply = <0xc2>;
				vdd-supply = <0xc3>;
				vddio-supply = <0xa2>;
				#address-cells = <0x01>;
				#size-cells = <0x00>;

				ports {
					#address-cells = <0x01>;
					#size-cells = <0x00>;

					port@0 {
						reg = <0x00>;

						endpoint {
							remote-endpoint = <0xae>;
							phandle = <0xac>;
						};
					};

					port@1 {
						reg = <0x01>;

						endpoint {
							remote-endpoint = <0xc8>;
							data-lanes = <0x00 0x01 0x02 0x03>;
							phandle = <0xc7>;
						};
					};
				};

				panel@0 {
					compatible = "sony,sirius-panel";
					reg = <0x00>;
					vddio-supply = <0xc3>;
					vsp-supply = <0xc4>;
					reset-gpios = <0x9a 0x13 0x01>;
					backlight = <0xc5>;
					pinctrl-0 = <0xc6>;
					pinctrl-names = "default";

					port {

						endpoint {
							remote-endpoint = <0xc7>;
							phandle = <0xc8>;
						};
					};
				};
			};

			phy@fd922a00 {
				compatible = "qcom,dsi-phy-28nm-hpm";
				reg = <0xfd922a00 0xd4 0xfd922b00 0x280 0xfd922d80 0x30>;
				reg-names = "dsi_pll", "dsi_phy", "dsi_phy_regulator";
				#clock-cells = <0x01>;
				#phy-cells = <0x00>;
				clocks = <0x64 0x5d 0x13>;
				clock-names = "iface", "ref";
				status = "okay";
				vddio-supply = <0xa2>;
				phandle = <0xa7>;
			};

			dsi@fd922e00 {
				compatible = "qcom,msm8974-dsi-ctrl", "qcom,mdss-dsi-ctrl";
				reg = <0xfd922e00 0x1f8>;
				reg-names = "dsi_ctrl";
				interrupt-parent = <0xa9>;
				interrupts = <0x04>;
				assigned-clocks = <0x64 0x22 0x64 0x14>;
				assigned-clock-parents = <0xa8 0x00 0xa8 0x01>;
				clocks = <0x64 0x69 0x64 0x5d 0x64 0x5e 0x64 0x60 0x64 0x6c 0x64 0x65 0x64 0x6e>;
				clock-names = "mdp_core", "iface", "bus", "byte", "pixel", "core", "core_mmss";
				phys = <0xa8>;
				status = "disabled";
				#address-cells = <0x01>;
				#size-cells = <0x00>;

				ports {
					#address-cells = <0x01>;
					#size-cells = <0x00>;

					port@0 {
						reg = <0x00>;

						endpoint {
							remote-endpoint = <0xaf>;
							phandle = <0xad>;
						};
					};

					port@1 {
						reg = <0x01>;

						endpoint {
						};
					};
				};
			};

			phy@fd923000 {
				compatible = "qcom,dsi-phy-28nm-hpm";
				reg = <0xfd923000 0xd4 0xfd923100 0x280 0xfd923380 0x30>;
				reg-names = "dsi_pll", "dsi_phy", "dsi_phy_regulator";
				#clock-cells = <0x01>;
				#phy-cells = <0x00>;
				clocks = <0x64 0x5d 0x13>;
				clock-names = "iface", "ref";
				status = "disabled";
				phandle = <0xa8>;
			};
		};

		cci@fda0c000 {
			compatible = "qcom,msm8974-cci";
			#address-cells = <0x01>;
			#size-cells = <0x00>;
			reg = <0xfda0c000 0x1000>;
			interrupts = <0x00 0x32 0x01>;
			clocks = <0x64 0x55 0x64 0x2c 0x64 0x2d>;
			clock-names = "camss_top_ahb", "cci_ahb", "cci";
			pinctrl-names = "default", "sleep";
			pinctrl-0 = <0xb0>;
			pinctrl-1 = <0xb1>;
			status = "disabled";

			i2c-bus@0 {
				reg = <0x00>;
				clock-frequency = <0x186a0>;
				#address-cells = <0x01>;
				#size-cells = <0x00>;
			};

			i2c-bus@1 {
				reg = <0x01>;
				clock-frequency = <0x186a0>;
				#address-cells = <0x01>;
				#size-cells = <0x00>;
			};
		};

		gpu@fdb00000 {
			compatible = "qcom,adreno-330.2", "qcom,adreno";
			reg = <0xfdb00000 0x10000>;
			reg-names = "kgsl_3d0_reg_memory";
			interrupts = <0x00 0x21 0x04>;
			interrupt-names = "kgsl_3d0_irq";
			clocks = <0x64 0x77 0x64 0x78 0x64 0x79>;
			clock-names = "core", "iface", "mem_iface";
			sram = <0xb2>;
			power-domains = <0x64 0x05>;
			operating-points-v2 = <0xb3>;
			interconnects = <0xaa 0x00 0xab 0x05 0xb4 0x0a 0xb4 0x0b>;
			interconnect-names = "gfx-mem", "ocmem";
			status = "okay";

			opp-table {
				compatible = "operating-points-v2";
				phandle = <0xb3>;

				opp-320000000 {
					opp-hz = <0x00 0x1312d000>;
				};

				opp-200000000 {
					opp-hz = <0x00 0xbebc200>;
				};

				opp-27000000 {
					opp-hz = <0x00 0x19bfcc0>;
				};
			};
		};

		sram@fdd00000 {
			compatible = "qcom,msm8974-ocmem";
			reg = <0xfdd00000 0x2000 0xfec00000 0x180000>;
			reg-names = "ctrl", "mem";
			ranges = <0x00 0xfec00000 0x180000>;
			clocks = <0x49 0x22 0x64 0x74>;
			clock-names = "core", "iface";
			#address-cells = <0x01>;
			#size-cells = <0x01>;

			gmu-sram@0 {
				reg = <0x00 0x100000>;
				phandle = <0xb2>;
			};
		};

		remoteproc@fe200000 {
			compatible = "qcom,msm8974-adsp-pil";
			reg = <0xfe200000 0x100>;
			interrupts-extended = <0x01 0x00 0xa2 0x01 0xb5 0x00 0x01 0xb5 0x01 0x01 0xb5 0x02 0x01 0xb5 0x03 0x01>;
			interrupt-names = "wdog", "fatal", "ready", "handover", "stop-ack";
			clocks = <0x13>;
			clock-names = "xo";
			power-domains = <0x47 0x00>;
			power-domain-names = "cx";
			memory-region = <0xb6>;
			qcom,smem-states = <0xb7 0x00>;
			qcom,smem-state-names = "stop";
			status = "okay";

			smd-edge {
				interrupts = <0x00 0x9c 0x01>;
				mboxes = <0x12 0x08>;
				qcom,smd-edge = <0x01>;
				label = "lpass";
				apr {
					compatible = "qcom,apr-v2";
					qcom,smd-channels = "apr_audio_svc";
					qcom,domain = <0x04>;
					#address-cells = <0x01>;
					#size-cells = <0x00>;

					service@3 {
						compatible = "qcom,q6core";
						reg = <0x03>;
					};

					service@4 {
						compatible = "qcom,q6afe";
						reg = <0x04>;

						dais {
							compatible = "qcom,q6afe-dais";
							#address-cells = <0x01>;
							#size-cells = <0x00>;
							#sound-dai-cells = <0x01>;
							phandle = <0xca>;

							dai@22 {
								reg = <0x16>;
								qcom,sd-lines = <0x00>;
							};
						};
					};

					service@7 {
						compatible = "qcom,q6asm";
						reg = <0x07>;

						dais {
							compatible = "qcom,q6asm-dais";
							#address-cells = <0x01>;
							#size-cells = <0x00>;
							#sound-dai-cells = <0x01>;
							phandle = <0xcb>;

							dai@0 {
								reg = <0x00>;
							};
						};
					};

					service@8 {
						compatible = "qcom,q6adm";
						reg = <0x08>;

						routing {
							compatible = "qcom,q6adm-routing";
							#sound-dai-cells = <0x00>;
							phandle = <0xcc>;
						};
					};
				};
			};
		};

		sound@fe02f000 {
			compatible = "qcom,msm8974-sndcard";
			reg = <0xfe02f000 0x04>;
			reg-names = "lpaif_quat_mode_muxsel";
			model = "Sony Xperia Z2";
			pinctrl-names = "default";
			pinctrl-0 = <0xcf>;

			mm1-dai-link {
				link-name = "MultiMedia1";

				cpu {
					sound-dai = <0xcb 0x00>;
				};
			};

			quat-mi2s-dai-link {
				link-name = "Quaternary MI2S Playback";

				cpu {
					sound-dai = <0xca 0x16>;
				};

				platform {
					sound-dai = <0xcc>;
				};

				codec {
					sound-dai = <0xcd 0xce>;
				};
			};
		};
		sram@fe805000 {
			compatible = "qcom,msm8974-imem", "syscon", "simple-mfd";
			reg = <0xfe805000 0x1000>;

			reboot-mode {
				compatible = "syscon-reboot-mode";
				offset = <0x65c>;
			};
		};
	};

	thermal-zones {

		cpu0-thermal {
			polling-delay-passive = <0xfa>;
			polling-delay = <0x3e8>;
			thermal-sensors = <0xb8 0x05>;

			trips {

				trip0 {
					temperature = <0x124f8>;
					hysteresis = <0x7d0>;
					type = "passive";
				};

				trip1 {
					temperature = <0x1adb0>;
					hysteresis = <0x7d0>;
					type = "critical";
				};
			};
		};

		cpu1-thermal {
			polling-delay-passive = <0xfa>;
			polling-delay = <0x3e8>;
			thermal-sensors = <0xb8 0x06>;

			trips {

				trip0 {
					temperature = <0x124f8>;
					hysteresis = <0x7d0>;
					type = "passive";
				};

				trip1 {
					temperature = <0x1adb0>;
					hysteresis = <0x7d0>;
					type = "critical";
				};
			};
		};

		cpu2-thermal {
			polling-delay-passive = <0xfa>;
			polling-delay = <0x3e8>;
			thermal-sensors = <0xb8 0x07>;

			trips {

				trip0 {
					temperature = <0x124f8>;
					hysteresis = <0x7d0>;
					type = "passive";
				};

				trip1 {
					temperature = <0x1adb0>;
					hysteresis = <0x7d0>;
					type = "critical";
				};
			};
		};

		cpu3-thermal {
			polling-delay-passive = <0xfa>;
			polling-delay = <0x3e8>;
			thermal-sensors = <0xb8 0x08>;

			trips {

				trip0 {
					temperature = <0x124f8>;
					hysteresis = <0x7d0>;
					type = "passive";
				};

				trip1 {
					temperature = <0x1adb0>;
					hysteresis = <0x7d0>;
					type = "critical";
				};
			};
		};

		q6-dsp-thermal {
			polling-delay-passive = <0xfa>;
			polling-delay = <0x3e8>;
			thermal-sensors = <0xb8 0x01>;

			trips {

				trip-point0 {
					temperature = <0x15f90>;
					hysteresis = <0x7d0>;
					type = "hot";
				};
			};
		};

		modemtx-thermal {
			polling-delay-passive = <0xfa>;
			polling-delay = <0x3e8>;
			thermal-sensors = <0xb8 0x02>;

			trips {

				trip-point0 {
					temperature = <0x15f90>;
					hysteresis = <0x7d0>;
					type = "hot";
				};
			};
		};

		video-thermal {
			polling-delay-passive = <0xfa>;
			polling-delay = <0x3e8>;
			thermal-sensors = <0xb8 0x03>;

			trips {

				trip-point0 {
					temperature = <0x17318>;
					hysteresis = <0x7d0>;
					type = "hot";
				};
			};
		};

		wlan-thermal {
			polling-delay-passive = <0xfa>;
			polling-delay = <0x3e8>;
			thermal-sensors = <0xb8 0x04>;

			trips {

				trip-point0 {
					temperature = <0x19a28>;
					hysteresis = <0x7d0>;
					type = "hot";
				};
			};
		};

		gpu-top-thermal {
			polling-delay-passive = <0xfa>;
			polling-delay = <0x3e8>;
			thermal-sensors = <0xb8 0x09>;

			trips {

				trip-point0 {
					temperature = <0x15f90>;
					hysteresis = <0x7d0>;
					type = "hot";
				};
			};
		};

		gpu-bottom-thermal {
			polling-delay-passive = <0xfa>;
			polling-delay = <0x3e8>;
			thermal-sensors = <0xb8 0x0a>;

			trips {

				trip-point0 {
					temperature = <0x15f90>;
					hysteresis = <0x7d0>;
					type = "hot";
				};
			};
		};

		pm8841-thermal {
			polling-delay-passive = <0x64>;
			polling-delay = <0x00>;
			thermal-sensors = <0xb9>;

			trips {

				trip0 {
					temperature = <0x19a28>;
					hysteresis = <0x7d0>;
					type = "passive";
				};

				trip1 {
					temperature = <0x1e848>;
					hysteresis = <0x7d0>;
					type = "hot";
				};

				crit {
					temperature = <0x222e0>;
					hysteresis = <0x7d0>;
					type = "critical";
				};
			};
		};

		pm8941-thermal {
			polling-delay-passive = <0x64>;
			polling-delay = <0x00>;
			thermal-sensors = <0xba>;

			trips {

				trip0 {
					temperature = <0x19a28>;
					hysteresis = <0x7d0>;
					type = "passive";
				};

				trip1 {
					temperature = <0x1e848>;
					hysteresis = <0x7d0>;
					type = "hot";
				};

				crit {
					temperature = <0x23668>;
					hysteresis = <0x7d0>;
					type = "critical";
				};
			};
		};
	};

	timer {
		compatible = "arm,armv7-timer";
		interrupts = <0x01 0x02 0xf08 0x01 0x03 0xf08 0x01 0x04 0xf08 0x01 0x01 0xf08>;
		clock-frequency = <0x124f800>;
	};

	aliases {
		mmc0 = "/soc/mmc@f9824900";
		mmc1 = "/soc/mmc@f98a4900";
		serial0 = "/soc/serial@f991e000";
		serial1 = "/soc/serial@f995d000";
	};

	gpio-keys {
		compatible = "gpio-keys";
		pinctrl-0 = <0xbb>;
		pinctrl-names = "default";

		key-volume-down {
			label = "volume_down";
			gpios = <0x9a 0x02 0x01>;
			linux,code = <0x72>;
			debounce-interval = <0x0f>;
		};

		key-volume-up {
			label = "volume_up";
			gpios = <0x9a 0x05 0x01>;
			linux,code = <0x73>;
			debounce-interval = <0x0f>;
		};

		key-camera-snapshot {
			label = "camera_snapshot";
			gpios = <0x9a 0x03 0x01>;
			linux,code = <0xd4>;
			debounce-interval = <0x0f>;
		};

		key-camera-focus {
			label = "camera_focus";
			gpios = <0x9a 0x04 0x01>;
			linux,code = <0x210>;
			debounce-interval = <0x0f>;
		};
	};

	battery {
		compatible = "simple-battery";
		voltage-min-design-microvolt = <0x30d400>;
		voltage-max-design-microvolt = <0x426030>;
		charge-full-design-microamp-hours = <0x30d400>;
		ocv-capacity-celsius = <0x19>;
		ocv-capacity-table-0 = <0x426030 0x64>, <0x4175d0 0x5f>, <0x40b280 0x5a>, <0x3fef30 0x55>, <0x3f2be0 0x50>, <0x3e6890 0x4b>, <0x3da540 0x46>, <0x3ce1f0 0x41>, <0x3c45b0 0x3c>, <0x3ba970 0x37>, <0x3b0d30 0x32>, <0x3a9800 0x2d>, <0x3a49e0 0x28>, <0x39fbc0 0x23>, <0x39ada0 0x1e>, <0x395f80 0x19>, <0x391160 0x14>, <0x389c30 0xf>, <0x382700 0xa>, <0x373ca0 0x5>, <0x33e140 0x0>;
		phandle = <0xc9>;
	};

	fuel-gauge {
		compatible = "adc-battery";
		io-channels = <0x9c 0x06>;
		io-channel-names = "voltage";
		monitored-battery = <0xc9>;
	};

	lcd-dcdc-regulator {
		compatible = "regulator-fixed";
		regulator-name = "vreg_vsp";
		regulator-min-microvolt = "", "Us";
		regulator-max-microvolt = "", "Us";
		gpio = <0x9a 0x14 0x00>;
		enable-active-high;
		pinctrl-0 = <0xbc>;
		pinctrl-names = "default";
		phandle = <0xc4>;
	};

	vreg-boost {
		compatible = "regulator-fixed";
		regulator-name = "vreg-boost";
		regulator-min-microvolt = <0x3010b0>;
		regulator-max-microvolt = <0x3010b0>;
		regulator-always-on;
		regulator-boot-on;
		gpio = <0x9a 0x15 0x00>;
		enable-active-high;
		pinctrl-names = "default";
		pinctrl-0 = <0xbd>;
		phandle = <0x18>;
	};

	vreg-vph-pwr {
		compatible = "regulator-fixed";
		regulator-name = "vph-pwr";
		regulator-min-microvolt = <0x36ee80>;
		regulator-max-microvolt = <0x36ee80>;
		regulator-always-on;
	};

	wlan-regulator {
		compatible = "regulator-fixed";
		regulator-name = "wl-reg";
		regulator-min-microvolt = <0x325aa0>;
		regulator-max-microvolt = <0x325aa0>;
		gpio = <0x9a 0x12 0x00>;
		enable-active-high;
		pinctrl-0 = <0xbe>;
		pinctrl-names = "default";
		phandle = <0x20>;
	};
};
